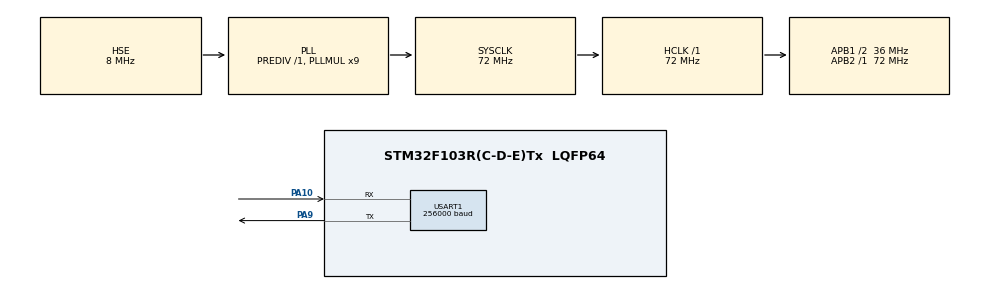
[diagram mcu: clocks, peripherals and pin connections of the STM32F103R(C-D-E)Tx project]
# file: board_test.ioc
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Mcu.Family=STM32F1
Mcu.Name=STM32F103R(C-D-E)Tx
Mcu.Package=LQFP64
NVIC.PriorityGroup=NVIC_PRIORITYGROUP_4
PA10.Mode=Asynchronous
PA10.Signal=USART1_RX
PA9.Mode=Asynchronous
PA9.Signal=USART1_TX
PD0-OSC_IN.Mode=HSE-External-Oscillator
PD0-OSC_IN.Signal=RCC_OSC_IN
PD1-OSC_OUT.Mode=HSE-External-Oscillator
PD1-OSC_OUT.Signal=RCC_OSC_OUT
ProjectManager.HeapSize=0x200
ProjectManager.StackSize=0x400
ProjectManager.TargetToolchain=MDK-ARM V5
RCC.AHBFreq_Value=72000000
RCC.APB1CLKDivider=RCC_HCLK_DIV2
RCC.APB1Freq_Value=36000000
RCC.APB1TimCLKDivider=1
RCC.APB1TimFreq_Value=36000000
RCC.APB2Freq_Value=72000000
RCC.APB2TimFreq_Value=72000000
RCC.HCLKFreq_Value=72000000
RCC.HSIState=RCC_HSI_ON
RCC.PLLMUL=RCC_PLL_MUL9
RCC.PLLSourceVirtual=RCC_PLLSOURCE_HSE
RCC.SYSCLKFreq_VALUE=72000000
RCC.SYSCLKSource=RCC_SYSCLKSOURCE_PLLCLK
RCC.USBFreq_Value=72000000
USART1.BaudRate=256000
board=board_test

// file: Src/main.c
/**
  ******************************************************************************
  * File Name          : main.c
  * Description        : Main program body
  ******************************************************************************
  *
  * COPYRIGHT(c) 2016 STMicroelectronics
  *
  * Redistribution and use in source and binary forms, with or without modification,
  * are permitted provided that the following conditions are met:
  *   1. Redistributions of source code must retain the above copyright notice,
  *      this list of conditions and the following disclaimer.
  *   2. Redistributions in binary form must reproduce the above copyright notice,
  *      this list of conditions and the following disclaimer in the documentation
  *      and/or other materials provided with the distribution.
  *   3. Neither the name of STMicroelectronics nor the names of its contributors
  *      may be used to endorse or promote products derived from this software
  *      without specific prior written permission.
  *
  * THIS SOFTWARE IS PROVIDED BY THE COPYRIGHT HOLDERS AND CONTRIBUTORS "AS IS"
  * AND ANY EXPRESS OR IMPLIED WARRANTIES, INCLUDING, BUT NOT LIMITED TO, THE
  * IMPLIED WARRANTIES OF MERCHANTABILITY AND FITNESS FOR A PARTICULAR PURPOSE ARE
  * DISCLAIMED. IN NO EVENT SHALL THE COPYRIGHT HOLDER OR CONTRIBUTORS BE LIABLE
  * FOR ANY DIRECT, INDIRECT, INCIDENTAL, SPECIAL, EXEMPLARY, OR CONSEQUENTIAL
  * DAMAGES (INCLUDING, BUT NOT LIMITED TO, PROCUREMENT OF SUBSTITUTE GOODS OR
  * SERVICES; LOSS OF USE, DATA, OR PROFITS; OR BUSINESS INTERRUPTION) HOWEVER
  * CAUSED AND ON ANY THEORY OF LIABILITY, WHETHER IN CONTRACT, STRICT LIABILITY,
  * OR TORT (INCLUDING NEGLIGENCE OR OTHERWISE) ARISING IN ANY WAY OUT OF THE USE
  * OF THIS SOFTWARE, EVEN IF ADVISED OF THE POSSIBILITY OF SUCH DAMAGE.
  *
  ******************************************************************************
  */
#include "stm32f1xx_hal.h"
#include "usart.h"
#include "gpio.h"

/* USER CODE BEGIN PV */
/* Private variables ---------------------------------------------------------*/

/* USER CODE END PV */

void SystemClock_Config(void);

/* USER CODE BEGIN PFP */
/* Private function prototypes -----------------------------------------------*/

/* USER CODE END PFP */

/* USER CODE BEGIN 0 */
/*
 * TimesNewRoman16.c
 *
 *  Created on: 11 июня 2016 г.
 *      Author: Администратор
 */

uint8_t TimesNewRoman16 [] =
{
/* char00 ('zero') */
0x00,0x00,0x00,0x00,0x00,0x00,0x00,0x00,
0x00,0x00,0x00,0x00,0x00,0x00,0x00,0x00,
0x00,0x00,0x00,0x00,0x00,0x00,0x00,0x00,
0x00,0x00,0x00,0x00,0x00,0x00,0x00,0x00,
0x00,0x00,0x00,0x00,0x00,0x00,0x00,0x00,
0x00,0x00,0x00,0x00,0x00,0x00,
/* char01 ('') */
0x00,0x00,0x00,0x00,0x00,0x00,0x00,0x00,
0x00,0x00,0x00,0x00,0x00,0x00,0x00,0x00,
0x00,0x00,0x00,0x00,0x00,0x00,0x00,0x00,
0x00,0x00,0x00,0x00,0x00,0x00,0x00,0x00,
0x00,0x00,0x00,0x00,0x00,0x00,0x00,0x00,
0x00,0x00,0x00,0x00,0x00,0x00,
/* char02 ('') */
0x00,0x00,0x00,0x00,0x00,0x00,0x00,0x00,
0x00,0x00,0x00,0x00,0x00,0x00,0x00,0x00,
0x00,0x00,0x00,0x00,0x00,0x00,0x00,0x00,
0x00,0x00,0x00,0x00,0x00,0x00,0x00,0x00,
0x00,0x00,0x00,0x00,0x00,0x00,0x00,0x00,
0x00,0x00,0x00,0x00,0x00,0x00,
/* char03 ('') */
0x00,0x00,0x00,0x00,0x00,0x00,0x00,0x00,
0x00,0x00,0x00,0x00,0x00,0x00,0x00,0x00,
0x00,0x00,0x00,0x00,0x00,0x00,0x00,0x00,
0x00,0x00,0x00,0x00,0x00,0x00,0x00,0x00,
0x00,0x00,0x00,0x00,0x00,0x00,0x00,0x00,
0x00,0x00,0x00,0x00,0x00,0x00,
/* char04 ('') */
0x00,0x00,0x00,0x00,0x00,0x00,0x00,0x00,
0x00,0x00,0x00,0x00,0x00,0x00,0x00,0x00,
0x00,0x00,0x00,0x00,0x00,0x00,0x00,0x00,
0x00,0x00,0x00,0x00,0x00,0x00,0x00,0x00,
0x00,0x00,0x00,0x00,0x00,0x00,0x00,0x00,
0x00,0x00,0x00,0x00,0x00,0x00,
/* char05 ('') */
0x00,0x00,0x00,0x00,0x00,0x00,0x00,0x00,
0x00,0x00,0x00,0x00,0x00,0x00,0x00,0x00,
0x00,0x00,0x00,0x00,0x00,0x00,0x00,0x00,
0x00,0x00,0x00,0x00,0x00,0x00,0x00,0x00,
0x00,0x00,0x00,0x00,0x00,0x00,0x00,0x00,
0x00,0x00,0x00,0x00,0x00,0x00,
/* char06 ('') */
0x00,0x00,0x00,0x00,0x00,0x00,0x00,0x00,
0x00,0x00,0x00,0x00,0x00,0x00,0x00,0x00,
0x00,0x00,0x00,0x00,0x00,0x00,0x00,0x00,
0x00,0x00,0x00,0x00,0x00,0x00,0x00,0x00,
0x00,0x00,0x00,0x00,0x00,0x00,0x00,0x00,
0x00,0x00,0x00,0x00,0x00,0x00,
/* char07 ('') */
0x00,0x00,0x00,0x00,0x00,0x00,0x00,0x00,
0x00,0x00,0x00,0x00,0x00,0x00,0x00,0x00,
0x00,0x00,0x00,0x00,0x00,0x00,0x00,0x00,
0x00,0x00,0x00,0x00,0x00,0x00,0x00,0x00,
0x00,0x00,0x00,0x00,0x00,0x00,0x00,0x00,
0x00,0x00,0x00,0x00,0x00,0x00,
/* char08 ('') */
0x00,0x00,0x00,0x00,0x00,0x00,0x00,0x00,
0x00,0x00,0x00,0x00,0x00,0x00,0x00,0x00,
0x00,0x00,0x00,0x00,0x00,0x00,0x00,0x00,
0x00,0x00,0x00,0x00,0x00,0x00,0x00,0x00,
0x00,0x00,0x00,0x00,0x00,0x00,0x00,0x00,
0x00,0x00,0x00,0x00,0x00,0x00,
/* char09 ('	') */
0x00,0x00,0x00,0x00,0x00,0x00,0x00,0x00,
0x00,0x00,0x00,0x00,0x00,0x00,0x00,0x00,
0x00,0x00,0x00,0x00,0x00,0x00,0x00,0x00,
0x00,0x00,0x00,0x00,0x00,0x00,0x00,0x00,
0x00,0x00,0x00,0x00,0x00,0x00,0x00,0x00,
0x00,0x00,0x00,0x00,0x00,0x00,
/* char0A ('LF') */
0x00,0x00,0x00,0x00,0x00,0x00,0x00,0x00,
0x00,0x00,0x00,0x00,0x00,0x00,0x00,0x00,
0x00,0x00,0x00,0x00,0x00,0x00,0x00,0x00,
0x00,0x00,0x00,0x00,0x00,0x00,0x00,0x00,
0x00,0x00,0x00,0x00,0x00,0x00,0x00,0x00,
0x00,0x00,0x00,0x00,0x00,0x00,
/* char0B ('') */
0x00,0x00,0x00,0x00,0x00,0x00,0x00,0x00,
0x00,0x00,0x00,0x00,0x00,0x00,0x00,0x00,
0x00,0x00,0x00,0x00,0x00,0x00,0x00,0x00,
0x00,0x00,0x00,0x00,0x00,0x00,0x00,0x00,
0x00,0x00,0x00,0x00,0x00,0x00,0x00,0x00,
0x00,0x00,0x00,0x00,0x00,0x00,
/* char0C ('') */
0x00,0x00,0x00,0x00,0x00,0x00,0x00,0x00,
0x00,0x00,0x00,0x00,0x00,0x00,0x00,0x00,
0x00,0x00,0x00,0x00,0x00,0x00,0x00,0x00,
0x00,0x00,0x00,0x00,0x00,0x00,0x00,0x00,
0x00,0x00,0x00,0x00,0x00,0x00,0x00,0x00,
0x00,0x00,0x00,0x00,0x00,0x00,
/* char0D ('CR') */
0x00,0x00,0x00,0x00,0x00,0x00,0x00,0x00,
0x00,0x00,0x00,0x00,0x00,0x00,0x00,0x00,
0x00,0x00,0x00,0x00,0x00,0x00,0x00,0x00,
0x00,0x00,0x00,0x00,0x00,0x00,0x00,0x00,
0x00,0x00,0x00,0x00,0x00,0x00,0x00,0x00,
0x00,0x00,0x00,0x00,0x00,0x00,
/* char0E ('') */
0x00,0x00,0x00,0x00,0x00,0x00,0x00,0x00,
0x00,0x00,0x00,0x00,0x00,0x00,0x00,0x00,
0x00,0x00,0x00,0x00,0x00,0x00,0x00,0x00,
0x00,0x00,0x00,0x00,0x00,0x00,0x00,0x00,
0x00,0x00,0x00,0x00,0x00,0x00,0x00,0x00,
0x00,0x00,0x00,0x00,0x00,0x00,
/* char0F ('') */
0x00,0x00,0x00,0x00,0x00,0x00,0x00,0x00,
0x00,0x00,0x00,0x00,0x00,0x00,0x00,0x00,
0x00,0x00,0x00,0x00,0x00,0x00,0x00,0x00,
0x00,0x00,0x00,0x00,0x00,0x00,0x00,0x00,
0x00,0x00,0x00,0x00,0x00,0x00,0x00,0x00,
0x00,0x00,0x00,0x00,0x00,0x00,
/* char10 ('') */
0x00,0x00,0x00,0x00,0x00,0x00,0x00,0x00,
0x00,0x00,0x00,0x00,0x00,0x00,0x00,0x00,
0x00,0x00,0x00,0x00,0x00,0x00,0x00,0x00,
0x00,0x00,0x00,0x00,0x00,0x00,0x00,0x00,
0x00,0x00,0x00,0x00,0x00,0x00,0x00,0x00,
0x00,0x00,0x00,0x00,0x00,0x00,
/* char11 ('') */
0x00,0x00,0x00,0x00,0x00,0x00,0x00,0x00,
0x00,0x00,0x00,0x00,0x00,0x00,0x00,0x00,
0x00,0x00,0x00,0x00,0x00,0x00,0x00,0x00,
0x00,0x00,0x00,0x00,0x00,0x00,0x00,0x00,
0x00,0x00,0x00,0x00,0x00,0x00,0x00,0x00,
0x00,0x00,0x00,0x00,0x00,0x00,
/* char12 ('') */
0x00,0x00,0x00,0x00,0x00,0x00,0x00,0x00,
0x00,0x00,0x00,0x00,0x00,0x00,0x00,0x00,
0x00,0x00,0x00,0x00,0x00,0x00,0x00,0x00,
0x00,0x00,0x00,0x00,0x00,0x00,0x00,0x00,
0x00,0x00,0x00,0x00,0x00,0x00,0x00,0x00,
0x00,0x00,0x00,0x00,0x00,0x00,
/* char13 ('') */
0x00,0x00,0x00,0x00,0x00,0x00,0x00,0x00,
0x00,0x00,0x00,0x00,0x00,0x00,0x00,0x00,
0x00,0x00,0x00,0x00,0x00,0x00,0x00,0x00,
0x00,0x00,0x00,0x00,0x00,0x00,0x00,0x00,
0x00,0x00,0x00,0x00,0x00,0x00,0x00,0x00,
0x00,0x00,0x00,0x00,0x00,0x00,
/* char14 ('') */
0x00,0x00,0x00,0x00,0x00,0x00,0x00,0x00,
0x00,0x00,0x00,0x00,0x00,0x00,0x00,0x00,
0x00,0x00,0x00,0x00,0x00,0x00,0x00,0x00,
0x00,0x00,0x00,0x00,0x00,0x00,0x00,0x00,
0x00,0x00,0x00,0x00,0x00,0x00,0x00,0x00,
0x00,0x00,0x00,0x00,0x00,0x00,
/* char15 ('') */
0x00,0x00,0x00,0x00,0x00,0x00,0x00,0x00,
0x00,0x00,0x00,0x00,0x00,0x00,0x00,0x00,
0x00,0x00,0x00,0x00,0x00,0x00,0x00,0x00,
0x00,0x00,0x00,0x00,0x00,0x00,0x00,0x00,
0x00,0x00,0x00,0x00,0x00,0x00,0x00,0x00,
0x00,0x00,0x00,0x00,0x00,0x00,
/* char16 ('') */
0x00,0x00,0x00,0x00,0x00,0x00,0x00,0x00,
0x00,0x00,0x00,0x00,0x00,0x00,0x00,0x00,
0x00,0x00,0x00,0x00,0x00,0x00,0x00,0x00,
0x00,0x00,0x00,0x00,0x00,0x00,0x00,0x00,
0x00,0x00,0x00,0x00,0x00,0x00,0x00,0x00,
0x00,0x00,0x00,0x00,0x00,0x00,
/* char17 ('') */
0x00,0x00,0x00,0x00,0x00,0x00,0x00,0x00,
0x00,0x00,0x00,0x00,0x00,0x00,0x00,0x00,
0x00,0x00,0x00,0x00,0x00,0x00,0x00,0x00,
0x00,0x00,0x00,0x00,0x00,0x00,0x00,0x00,
0x00,0x00,0x00,0x00,0x00,0x00,0x00,0x00,
0x00,0x00,0x00,0x00,0x00,0x00,
/* char18 ('') */
0x00,0x00,0x00,0x00,0x00,0x00,0x00,0x00,
0x00,0x00,0x00,0x00,0x00,0x00,0x00,0x00,
0x00,0x00,0x00,0x00,0x00,0x00,0x00,0x00,
0x00,0x00,0x00,0x00,0x00,0x00,0x00,0x00,
0x00,0x00,0x00,0x00,0x00,0x00,0x00,0x00,
0x00,0x00,0x00,0x00,0x00,0x00,
/* char19 ('end of medium') */
0x00,0x00,0x00,0x00,0x00,0x00,0x00,0x00,
0x00,0x00,0x00,0x00,0x00,0x00,0x00,0x00,
0x00,0x00,0x00,0x00,0x00,0x00,0x00,0x00,
0x00,0x00,0x00,0x00,0x00,0x00,0x00,0x00,
0x00,0x00,0x00,0x00,0x00,0x00,0x00,0x00,
0x00,0x00,0x00,0x00,0x00,0x00,
/* char1A ('substitute') */
0x00,0x00,0x00,0x00,0x00,0x00,0x00,0x00,
0x00,0x00,0x00,0x00,0x00,0x00,0x00,0x00,
0x00,0x00,0x00,0x00,0x00,0x00,0x00,0x00,
0x00,0x00,0x00,0x00,0x00,0x00,0x00,0x00,
0x00,0x00,0x00,0x00,0x00,0x00,0x00,0x00,
0x00,0x00,0x00,0x00,0x00,0x00,
/* char1B ('') */
0x00,0x00,0x00,0x00,0x00,0x00,0x00,0x00,
0x00,0x00,0x00,0x00,0x00,0x00,0x00,0x00,
0x00,0x00,0x00,0x00,0x00,0x00,0x00,0x00,
0x00,0x00,0x00,0x00,0x00,0x00,0x00,0x00,
0x00,0x00,0x00,0x00,0x00,0x00,0x00,0x00,
0x00,0x00,0x00,0x00,0x00,0x00,
/* char1C ('') */
0x00,0x00,0x00,0x00,0x00,0x00,0x00,0x00,
0x00,0x00,0x00,0x00,0x00,0x00,0x00,0x00,
0x00,0x00,0x00,0x00,0x00,0x00,0x00,0x00,
0x00,0x00,0x00,0x00,0x00,0x00,0x00,0x00,
0x00,0x00,0x00,0x00,0x00,0x00,0x00,0x00,
0x00,0x00,0x00,0x00,0x00,0x00,
/* char1D ('') */
0x00,0x00,0x00,0x00,0x00,0x00,0x00,0x00,
0x00,0x00,0x00,0x00,0x00,0x00,0x00,0x00,
0x00,0x00,0x00,0x00,0x00,0x00,0x00,0x00,
0x00,0x00,0x00,0x00,0x00,0x00,0x00,0x00,
0x00,0x00,0x00,0x00,0x00,0x00,0x00,0x00,
0x00,0x00,0x00,0x00,0x00,0x00,
/* char1E ('') */
0x00,0x00,0x00,0x00,0x00,0x00,0x00,0x00,
0x00,0x00,0x00,0x00,0x00,0x00,0x00,0x00,
0x00,0x00,0x00,0x00,0x00,0x00,0x00,0x00,
0x00,0x00,0x00,0x00,0x00,0x00,0x00,0x00,
0x00,0x00,0x00,0x00,0x00,0x00,0x00,0x00,
0x00,0x00,0x00,0x00,0x00,0x00,
/* char1F ('') */
0x00,0x00,0x00,0x00,0x00,0x00,0x00,0x00,
0x00,0x00,0x00,0x00,0x00,0x00,0x00,0x00,
0x00,0x00,0x00,0x00,0x00,0x00,0x00,0x00,
0x00,0x00,0x00,0x00,0x00,0x00,0x00,0x00,
0x00,0x00,0x00,0x00,0x00,0x00,0x00,0x00,
0x00,0x00,0x00,0x00,0x00,0x00,
/* char20 (' ') */
0x00,0x00,0x00,0x00,0x00,0x00,0x00,0x00,
0x00,0x00,0x00,0x00,0x00,0x00,0x00,0x00,
0x00,0x00,0x00,0x00,0x00,0x00,0x00,0x00,
0x00,0x00,0x00,0x00,0x00,0x00,0x00,0x00,
0x00,0x00,0x00,0x00,0x00,0x00,0x00,0x00,
0x00,0x00,0x00,0x00,0x00,0x00,
/* char21 ('!') */
0x00,0x00,0x00,0x00,0x00,0x00,0x00,0x00,
0x00,0x00,0x30,0x00,0x30,0x00,0x00,0x00,
0x00,0x00,0x20,0x00,0x20,0x00,0x20,0x00,
0x20,0x00,0x30,0x00,0x30,0x00,0x30,0x00,
0x30,0x00,0x30,0x00,0x30,0x00,0x00,0x00,
0x00,0x00,0x00,0x00,0x00,0x00,
/* char22 ('"') */
0x00,0x00,0x00,0x00,0x00,0x00,0x00,0x00,
0x00,0x00,0x00,0x00,0x00,0x00,0x00,0x00,
0x00,0x00,0x00,0x00,0x00,0x00,0x00,0x00,
0x00,0x00,0x44,0x00,0x44,0x00,0x66,0x00,
0x66,0x00,0x66,0x00,0x66,0x00,0x00,0x00,
0x00,0x00,0x00,0x00,0x00,0x00,
/* char23 ('#') */
0x00,0x00,0x00,0x00,0x00,0x00,0x00,0x00,
0x00,0x00,0x42,0x00,0x42,0x00,0x42,0x00,
0x21,0x00,0x21,0x00,0xFF,0xE0,0x21,0x00,
0x21,0x00,0x10,0x80,0xFF,0xE0,0x10,0x80,
0x10,0x80,0x10,0x80,0x08,0x40,0x08,0x40,
0x00,0x00,0x00,0x00,0x00,0x00,
/* char24 ('$') */
0x00,0x00,0x00,0x00,0x00,0x00,0x00,0x00,
0x04,0x00,0x3F,0x00,0x65,0x80,0x44,0xC0,
0x44,0xC0,0x04,0xC0,0x05,0x80,0x07,0x00,
0x1E,0x00,0x3C,0x00,0x74,0x00,0x64,0x80,
0x64,0x80,0x35,0x80,0x1F,0x00,0x04,0x00,
0x00,0x00,0x00,0x00,0x00,0x00,
/* char25 ('') */
0x00,0x00,0x00,0x00,0x00,0x00,0x00,0x00,
0x00,0x00,0x10,0x07,0x08,0x0D,0x04,0x18,
0x02,0x18,0x01,0x18,0x01,0x18,0x38,0x8D,
0x6C,0x47,0xC6,0x20,0xC6,0x20,0xC6,0x10,
0xC6,0x08,0x6C,0x04,0x38,0x02,0x00,0x00,
0x00,0x00,0x00,0x00,0x00,0x00,
/* char26 ('&') */
0x00,0x00,0x00,0x00,0x00,0x00,0x00,0x00,
0x00,0x00,0x3E,0x1C,0x71,0x7E,0x60,0xE3,
0x60,0xC0,0x61,0xC0,0x23,0xA0,0x13,0x10,
0x0E,0x18,0x07,0x3C,0x0C,0x80,0x0C,0x40,
0x0C,0x40,0x0C,0x40,0x07,0x80,0x00,0x00,
0x00,0x00,0x00,0x00,0x00,0x00,
/* char27 (''') */
0x00,0x00,0x00,0x00,0x00,0x00,0x00,0x00,
0x00,0x00,0x00,0x00,0x00,0x00,0x00,0x00,
0x00,0x00,0x00,0x00,0x00,0x00,0x00,0x00,
0x00,0x00,0x40,0x00,0x40,0x00,0x60,0x00,
0x60,0x00,0x60,0x00,0x60,0x00,0x00,0x00,
0x00,0x00,0x00,0x00,0x00,0x00,
/* char28 ('(') */
0x00,0x00,0x02,0x00,0x04,0x00,0x08,0x00,
0x10,0x00,0x30,0x00,0x30,0x00,0x60,0x00,
0x60,0x00,0x60,0x00,0x60,0x00,0x60,0x00,
0x60,0x00,0x60,0x00,0x20,0x00,0x30,0x00,
0x10,0x00,0x08,0x00,0x04,0x00,0x02,0x00,
0x00,0x00,0x00,0x00,0x00,0x00,
/* char29 (')') */
0x00,0x00,0x80,0x00,0x40,0x00,0x20,0x00,
0x10,0x00,0x18,0x00,0x08,0x00,0x0C,0x00,
0x0C,0x00,0x0C,0x00,0x0C,0x00,0x0C,0x00,
0x0C,0x00,0x0C,0x00,0x08,0x00,0x18,0x00,
0x10,0x00,0x20,0x00,0x40,0x00,0x80,0x00,
0x00,0x00,0x00,0x00,0x00,0x00,
/* char2A ('*') */
0x00,0x00,0x00,0x00,0x00,0x00,0x00,0x00,
0x00,0x00,0x00,0x00,0x00,0x00,0x00,0x00,
0x00,0x00,0x00,0x00,0x00,0x00,0x04,0x00,
0x04,0x00,0x35,0x80,0x35,0x80,0x0E,0x00,
0x35,0x80,0x35,0x80,0x04,0x00,0x04,0x00,
0x00,0x00,0x00,0x00,0x00,0x00,
/* char2B ('+') */
0x00,0x00,0x00,0x00,0x00,0x00,0x00,0x00,
0x00,0x00,0x00,0x00,0x00,0x00,0x04,0x00,
0x04,0x00,0x04,0x00,0x04,0x00,0x04,0x00,
0xFF,0xE0,0x04,0x00,0x04,0x00,0x04,0x00,
0x04,0x00,0x04,0x00,0x00,0x00,0x00,0x00,
0x00,0x00,0x00,0x00,0x00,0x00,
/* char2C (',') */
0x00,0x00,0x00,0x00,0x40,0x00,0x20,0x00,
0x10,0x00,0x70,0x00,0x60,0x00,0x00,0x00,
0x00,0x00,0x00,0x00,0x00,0x00,0x00,0x00,
0x00,0x00,0x00,0x00,0x00,0x00,0x00,0x00,
0x00,0x00,0x00,0x00,0x00,0x00,0x00,0x00,
0x00,0x00,0x00,0x00,0x00,0x00,
/* char2D ('-') */
0x00,0x00,0x00,0x00,0x00,0x00,0x00,0x00,
0x00,0x00,0x00,0x00,0x00,0x00,0x00,0x00,
0x00,0x00,0x7C,0x00,0x7C,0x00,0x00,0x00,
0x00,0x00,0x00,0x00,0x00,0x00,0x00,0x00,
0x00,0x00,0x00,0x00,0x00,0x00,0x00,0x00,
0x00,0x00,0x00,0x00,0x00,0x00,
/* char2E ('.') */
0x00,0x00,0x00,0x00,0x00,0x00,0x00,0x00,
0x00,0x00,0x60,0x00,0x60,0x00,0x00,0x00,
0x00,0x00,0x00,0x00,0x00,0x00,0x00,0x00,
0x00,0x00,0x00,0x00,0x00,0x00,0x00,0x00,
0x00,0x00,0x00,0x00,0x00,0x00,0x00,0x00,
0x00,0x00,0x00,0x00,0x00,0x00,
/* char2F ('/') */
0x00,0x00,0x00,0x00,0x00,0x00,0x00,0x00,
0x00,0x00,0x80,0x00,0x80,0x00,0x40,0x00,
0x40,0x00,0x40,0x00,0x20,0x00,0x20,0x00,
0x20,0x00,0x10,0x00,0x10,0x00,0x10,0x00,
0x08,0x00,0x08,0x00,0x08,0x00,0x04,0x00,
0x00,0x00,0x00,0x00,0x00,0x00,
/* char30 ('0') */
0x00,0x00,0x00,0x00,0x00,0x00,0x00,0x00,
0x00,0x00,0x0E,0x00,0x11,0x00,0x31,0x80,
0x20,0x80,0x60,0xC0,0x60,0xC0,0x60,0xC0,
0x60,0xC0,0x60,0xC0,0x60,0xC0,0x20,0x80,
0x31,0x80,0x11,0x00,0x0E,0x00,0x00,0x00,
0x00,0x00,0x00,0x00,0x00,0x00,
/* char31 ('1') */
0x00,0x00,0x00,0x00,0x00,0x00,0x00,0x00,
0x00,0x00,0x3F,0x00,0x0C,0x00,0x0C,0x00,
0x0C,0x00,0x0C,0x00,0x0C,0x00,0x0C,0x00,
0x0C,0x00,0x0C,0x00,0x0C,0x00,0x0C,0x00,
0x0C,0x00,0x3C,0x00,0x0C,0x00,0x00,0x00,
0x00,0x00,0x00,0x00,0x00,0x00,
/* char32 ('2') */
0x00,0x00,0x00,0x00,0x00,0x00,0x00,0x00,
0x00,0x00,0x7F,0x80,0x3F,0xC0,0x10,0x40,
0x08,0x00,0x04,0x00,0x02,0x00,0x02,0x00,
0x01,0x00,0x01,0x80,0x01,0x80,0x41,0x80,
0x63,0x80,0x3F,0x00,0x1E,0x00,0x00,0x00,
0x00,0x00,0x00,0x00,0x00,0x00,
/* char33 ('3') */
0x00,0x00,0x00,0x00,0x00,0x00,0x00,0x00,
0x00,0x00,0x7C,0x00,0x63,0x00,0x01,0x00,
0x01,0x80,0x01,0x80,0x03,0x80,0x07,0x00,
0x1F,0x00,0x0C,0x00,0x02,0x00,0x03,0x00,
0x43,0x00,0x27,0x00,0x1E,0x00,0x00,0x00,
0x00,0x00,0x00,0x00,0x00,0x00,
/* char34 ('4') */
0x00,0x00,0x00,0x00,0x00,0x00,0x00,0x00,
0x00,0x00,0x03,0x00,0x03,0x00,0x03,0x00,
0x03,0x00,0xFF,0xC0,0x83,0x00,0x43,0x00,
0x23,0x00,0x13,0x00,0x13,0x00,0x0B,0x00,
0x07,0x00,0x03,0x00,0x03,0x00,0x00,0x00,
0x00,0x00,0x00,0x00,0x00,0x00,
/* char35 ('5') */
0x00,0x00,0x00,0x00,0x00,0x00,0x00,0x00,
0x00,0x00,0x7C,0x00,0x62,0x00,0x01,0x00,
0x00,0x80,0x00,0x80,0x01,0x80,0x01,0x80,
0x03,0x80,0x0F,0x00,0x3E,0x00,0x38,0x00,
0x10,0x00,0x1F,0x00,0x0F,0x80,0x00,0x00,
0x00,0x00,0x00,0x00,0x00,0x00,
/* char36 ('6') */
0x00,0x00,0x00,0x00,0x00,0x00,0x00,0x00,
0x00,0x00,0x0F,0x00,0x31,0x80,0x30,0x80,
0x60,0xC0,0x60,0xC0,0x60,0xC0,0x61,0xC0,
0x71,0x80,0x2F,0x00,0x30,0x00,0x18,0x00,
0x0C,0x00,0x06,0x00,0x01,0xC0,0x00,0x00,
0x00,0x00,0x00,0x00,0x00,0x00,
/* char37 ('7') */
0x00,0x00,0x00,0x00,0x00,0x00,0x00,0x00,
0x00,0x00,0x08,0x00,0x04,0x00,0x04,0x00,
0x04,0x00,0x02,0x00,0x02,0x00,0x02,0x00,
0x01,0x00,0x01,0x00,0x01,0x00,0x00,0x80,
0x40,0x80,0x3F,0x80,0x3F,0xC0,0x00,0x00,
0x00,0x00,0x00,0x00,0x00,0x00,
/* char38 ('8') */
0x00,0x00,0x00,0x00,0x00,0x00,0x00,0x00,
0x00,0x00,0x1F,0x00,0x31,0x80,0x60,0xC0,
0x60,0xC0,0x61,0xC0,0x33,0x80,0x0F,0x00,
0x1E,0x00,0x39,0x80,0x70,0xC0,0x60,0xC0,
0x60,0xC0,0x31,0x80,0x1F,0x00,0x00,0x00,
0x00,0x00,0x00,0x00,0x00,0x00,
/* char39 ('9') */
0x00,0x00,0x00,0x00,0x00,0x00,0x00,0x00,
0x00,0x00,0x70,0x00,0x0C,0x00,0x06,0x00,
0x01,0x00,0x01,0x80,0x1F,0x80,0x30,0xC0,
0x70,0xC0,0x60,0xC0,0x60,0xC0,0x60,0xC0,
0x21,0x80,0x31,0x80,0x1E,0x00,0x00,0x00,
0x00,0x00,0x00,0x00,0x00,0x00,
/* char3A (':') */
0x00,0x00,0x00,0x00,0x00,0x00,0x00,0x00,
0x00,0x00,0x30,0x00,0x30,0x00,0x00,0x00,
0x00,0x00,0x00,0x00,0x00,0x00,0x00,0x00,
0x00,0x00,0x30,0x00,0x30,0x00,0x00,0x00,
0x00,0x00,0x00,0x00,0x00,0x00,0x00,0x00,
0x00,0x00,0x00,0x00,0x00,0x00,
/* char3B (';') */
0x00,0x00,0x00,0x00,0x40,0x00,0x20,0x00,
0x10,0x00,0x70,0x00,0x60,0x00,0x00,0x00,
0x00,0x00,0x00,0x00,0x00,0x00,0x00,0x00,
0x00,0x00,0x60,0x00,0x60,0x00,0x00,0x00,
0x00,0x00,0x00,0x00,0x00,0x00,0x00,0x00,
0x00,0x00,0x00,0x00,0x00,0x00,
/* char3C ('<') */
0x00,0x00,0x00,0x00,0x00,0x00,0x00,0x00,
0x00,0x00,0x00,0x00,0x00,0x00,0x00,0x20,
0x00,0xC0,0x07,0x00,0x18,0x00,0x60,0x00,
0x80,0x00,0x60,0x00,0x18,0x00,0x07,0x00,
0x00,0xC0,0x00,0x20,0x00,0x00,0x00,0x00,
0x00,0x00,0x00,0x00,0x00,0x00,
/* char3D ('=') */
0x00,0x00,0x00,0x00,0x00,0x00,0x00,0x00,
0x00,0x00,0x00,0x00,0x00,0x00,0x00,0x00,
0x00,0x00,0x00,0x00,0xFF,0xF0,0x00,0x00,
0x00,0x00,0x00,0x00,0xFF,0xF0,0x00,0x00,
0x00,0x00,0x00,0x00,0x00,0x00,0x00,0x00,
0x00,0x00,0x00,0x00,0x00,0x00,
/* char3E ('>') */
0x00,0x00,0x00,0x00,0x00,0x00,0x00,0x00,
0x00,0x00,0x00,0x00,0x00,0x00,0x80,0x00,
0x60,0x00,0x1C,0x00,0x03,0x00,0x00,0xC0,
0x00,0x20,0x00,0xC0,0x03,0x00,0x1C,0x00,
0x60,0x00,0x80,0x00,0x00,0x00,0x00,0x00,
0x00,0x00,0x00,0x00,0x00,0x00,
/* char3F ('?') */
0x00,0x00,0x00,0x00,0x00,0x00,0x00,0x00,
0x00,0x00,0x0C,0x00,0x0C,0x00,0x00,0x00,
0x08,0x00,0x08,0x00,0x04,0x00,0x02,0x00,
0x03,0x00,0x01,0x00,0x61,0x80,0x61,0x80,
0x41,0x80,0x23,0x00,0x1E,0x00,0x00,0x00,
0x00,0x00,0x00,0x00,0x00,0x00,
/* char40 ('@') */
0x01,0xF8,0x06,0x06,0x08,0x01,0x10,0x00,
0x20,0x00,0x23,0x9E,0x46,0x79,0x46,0x18,
0x46,0x18,0x46,0x0C,0x43,0x0C,0x43,0x04,
0x61,0x84,0x21,0x86,0x20,0xCE,0x10,0x72,
0x18,0x00,0x0C,0x01,0x03,0x06,0x00,0xFC,
0x00,0x00,0x00,0x00,0x00,0x00,
/* char41 ('A') */
0x00,0x00,0x00,0x00,0x00,0x00,0x00,0x00,
0x00,0x00,0xF0,0x7C,0x60,0x38,0x20,0x30,
0x20,0x30,0x10,0x60,0x1F,0xE0,0x08,0x60,
0x08,0xC0,0x04,0xC0,0x04,0xC0,0x05,0x80,
0x03,0x80,0x03,0x00,0x01,0x00,0x00,0x00,
0x00,0x00,0x00,0x00,0x00,0x00,
/* char42 ('B') */
0x00,0x00,0x00,0x00,0x00,0x00,0x00,0x00,
0x00,0x00,0xFF,0xE0,0x30,0x30,0x30,0x18,
0x30,0x18,0x30,0x18,0x30,0x38,0x30,0x70,
0x3F,0xC0,0x30,0x60,0x30,0x30,0x30,0x30,
0x30,0x30,0x30,0x60,0xFF,0xC0,0x00,0x00,
0x00,0x00,0x00,0x00,0x00,0x00,
/* char43 ('C') */
0x00,0x00,0x00,0x00,0x00,0x00,0x00,0x00,
0x00,0x00,0x07,0xC0,0x1C,0x20,0x30,0x10,
0x30,0x08,0x60,0x00,0x60,0x00,0x60,0x00,
0x60,0x00,0x60,0x00,0x60,0x08,0x30,0x18,
0x10,0x18,0x0C,0x38,0x07,0xC8,0x00,0x00,
0x00,0x00,0x00,0x00,0x00,0x00,
/* char44 ('D') */
0x00,0x00,0x00,0x00,0x00,0x00,0x00,0x00,
0x00,0x00,0xFF,0xC0,0x30,0x60,0x30,0x30,
0x30,0x18,0x30,0x0C,0x30,0x0C,0x30,0x0C,
0x30,0x0C,0x30,0x0C,0x30,0x0C,0x30,0x18,
0x30,0x38,0x30,0x70,0xFF,0xC0,0x00,0x00,
0x00,0x00,0x00,0x00,0x00,0x00,
/* char45 ('E') */
0x00,0x00,0x00,0x00,0x00,0x00,0x00,0x00,
0x00,0x00,0xFF,0xF0,0x30,0x30,0x30,0x10,
0x30,0x08,0x30,0x00,0x30,0x40,0x30,0x40,
0x3F,0xC0,0x30,0x40,0x30,0x40,0x30,0x00,
0x30,0x10,0x30,0x30,0xFF,0xF0,0x00,0x00,
0x00,0x00,0x00,0x00,0x00,0x00,
/* char46 ('F') */
0x00,0x00,0x00,0x00,0x00,0x00,0x00,0x00,
0x00,0x00,0xFC,0x00,0x30,0x00,0x30,0x00,
0x30,0x00,0x30,0x00,0x30,0x80,0x30,0x80,
0x3F,0x80,0x30,0x80,0x30,0x80,0x30,0x00,
0x30,0x20,0x30,0x60,0xFF,0xE0,0x00,0x00,
0x00,0x00,0x00,0x00,0x00,0x00,
/* char47 ('G') */
0x00,0x00,0x00,0x00,0x00,0x00,0x00,0x00,
0x00,0x00,0x07,0xE0,0x1C,0x38,0x38,0x18,
0x30,0x18,0x60,0x18,0x60,0x18,0x60,0x18,
0x60,0x7E,0x60,0x00,0x20,0x00,0x30,0x08,
0x10,0x18,0x0C,0x38,0x07,0xC8,0x00,0x00,
0x00,0x00,0x00,0x00,0x00,0x00,
/* char48 ('H') */
0x00,0x00,0x00,0x00,0x00,0x00,0x00,0x00,
0x00,0x00,0xFC,0x7E,0x30,0x18,0x30,0x18,
0x30,0x18,0x30,0x18,0x30,0x18,0x30,0x18,
0x3F,0xF8,0x30,0x18,0x30,0x18,0x30,0x18,
0x30,0x18,0x30,0x18,0xFC,0x7E,0x00,0x00,
0x00,0x00,0x00,0x00,0x00,0x00,
/* char49 ('I') */
0x00,0x00,0x00,0x00,0x00,0x00,0x00,0x00,
0x00,0x00,0xFC,0x00,0x30,0x00,0x30,0x00,
0x30,0x00,0x30,0x00,0x30,0x00,0x30,0x00,
0x30,0x00,0x30,0x00,0x30,0x00,0x30,0x00,
0x30,0x00,0x30,0x00,0xFC,0x00,0x00,0x00,
0x00,0x00,0x00,0x00,0x00,0x00,
/* char4A ('J') */
0x00,0x00,0x00,0x00,0x00,0x00,0x00,0x00,
0x00,0x00,0x70,0x00,0xE8,0x00,0xCC,0x00,
0x0C,0x00,0x0C,0x00,0x0C,0x00,0x0C,0x00,
0x0C,0x00,0x0C,0x00,0x0C,0x00,0x0C,0x00,
0x0C,0x00,0x0C,0x00,0x3F,0x00,0x00,0x00,
0x00,0x00,0x00,0x00,0x00,0x00,
/* char4B ('K') */
0x00,0x00,0x00,0x00,0x00,0x00,0x00,0x00,
0x00,0x00,0xFC,0x7E,0x30,0x38,0x30,0x70,
0x30,0xE0,0x31,0xC0,0x33,0x80,0x37,0x00,
0x3E,0x00,0x32,0x00,0x31,0x00,0x30,0x80,
0x30,0x40,0x30,0x30,0xFC,0x7C,0x00,0x00,
0x00,0x00,0x00,0x00,0x00,0x00,
/* char4C ('L') */
0x00,0x00,0x00,0x00,0x00,0x00,0x00,0x00,
0x00,0x00,0xFF,0xE0,0x30,0x60,0x30,0x30,
0x30,0x10,0x30,0x00,0x30,0x00,0x30,0x00,
0x30,0x00,0x30,0x00,0x30,0x00,0x30,0x00,
0x30,0x00,0x30,0x00,0xFC,0x00,0x00,0x00,
0x00,0x00,0x00,0x00,0x00,0x00,
/* char4D ('M') */
0x00,0x00,0x00,0x00,0x00,0x00,0x00,0x00,
0x00,0x00,0xF8,0x8F,0x21,0x83,0x21,0xC3,
0x21,0xC3,0x23,0x23,0x23,0x23,0x27,0x13,
0x26,0x13,0x2E,0x0B,0x2C,0x0B,0x2C,0x0B,
0x3C,0x07,0x38,0x07,0xF8,0x03,0x00,0x00,
0x00,0x00,0x00,0x00,0x00,0x00,
/* char4E ('N') */
0x00,0x00,0x00,0x00,0x00,0x00,0x00,0x00,
0x00,0x00,0x7C,0x04,0x10,0x0C,0x10,0x1C,
0x10,0x3C,0x10,0x34,0x10,0x64,0x10,0xC4,
0x11,0x84,0x13,0x04,0x17,0x04,0x1E,0x04,
0x1C,0x04,0x38,0x04,0xF0,0x1E,0x00,0x00,
0x00,0x00,0x00,0x00,0x00,0x00,
/* char4F ('O') */
0x00,0x00,0x00,0x00,0x00,0x00,0x00,0x00,
0x00,0x00,0x07,0xC0,0x18,0x30,0x30,0x18,
0x30,0x18,0x60,0x0C,0x60,0x0C,0x60,0x0C,
0x60,0x0C,0x60,0x0C,0x60,0x0C,0x30,0x18,
0x30,0x18,0x18,0x30,0x07,0xC0,0x00,0x00,
0x00,0x00,0x00,0x00,0x00,0x00,
/* char50 ('P') */
0x00,0x00,0x00,0x00,0x00,0x00,0x00,0x00,
0x00,0x00,0xFC,0x00,0x30,0x00,0x30,0x00,
0x30,0x00,0x30,0x00,0x30,0x00,0x3F,0x80,
0x30,0xC0,0x30,0x60,0x30,0x60,0x30,0x60,
0x30,0x60,0x30,0xC0,0xFF,0x80,0x00,0x00,
0x00,0x00,0x00,0x00,0x00,0x00,
/* char51 ('Q') */
0x00,0x00,0x00,0x1C,0x00,0x70,0x00,0xC0,
0x03,0x80,0x07,0xC0,0x18,0x30,0x30,0x18,
0x30,0x18,0x60,0x0C,0x60,0x0C,0x60,0x0C,
0x60,0x0C,0x60,0x0C,0x60,0x0C,0x30,0x18,
0x30,0x18,0x18,0x30,0x07,0xC0,0x00,0x00,
0x00,0x00,0x00,0x00,0x00,0x00,
/* char52 ('R') */
0x00,0x00,0x00,0x00,0x00,0x00,0x00,0x00,
0x00,0x00,0xFC,0x3C,0x30,0x70,0x30,0xE0,
0x30,0xC0,0x31,0x80,0x33,0x80,0x33,0x00,
0x3F,0x80,0x30,0xC0,0x30,0x60,0x30,0x60,
0x30,0x60,0x30,0xC0,0xFF,0x80,0x00,0x00,
0x00,0x00,0x00,0x00,0x00,0x00,
/* char53 ('S') */
0x00,0x00,0x00,0x00,0x00,0x00,0x00,0x00,
0x00,0x00,0x4F,0x00,0x71,0x80,0x60,0xC0,
0x40,0xC0,0x41,0xC0,0x03,0x80,0x07,0x00,
0x1E,0x00,0x38,0x00,0x70,0x80,0x60,0x80,
0x61,0x80,0x33,0x80,0x1C,0x80,0x00,0x00,
0x00,0x00,0x00,0x00,0x00,0x00,
/* char54 ('T') */
0x00,0x00,0x00,0x00,0x00,0x00,0x00,0x00,
0x00,0x00,0x1F,0x80,0x06,0x00,0x06,0x00,
0x06,0x00,0x06,0x00,0x06,0x00,0x06,0x00,
0x06,0x00,0x06,0x00,0x06,0x00,0x06,0x00,
0x86,0x10,0xC6,0x30,0xFF,0xF0,0x00,0x00,
0x00,0x00,0x00,0x00,0x00,0x00,
/* char55 ('U') */
0x00,0x00,0x00,0x00,0x00,0x00,0x00,0x00,
0x00,0x00,0x07,0xC0,0x1C,0x30,0x18,0x10,
0x30,0x08,0x30,0x08,0x30,0x08,0x30,0x08,
0x30,0x08,0x30,0x08,0x30,0x08,0x30,0x08,
0x30,0x08,0x30,0x08,0xFC,0x3E,0x00,0x00,
0x00,0x00,0x00,0x00,0x00,0x00,
/* char56 ('V') */
0x00,0x00,0x00,0x00,0x00,0x00,0x00,0x00,
0x00,0x00,0x01,0x80,0x01,0x80,0x03,0x40,
0x03,0x40,0x03,0x40,0x06,0x20,0x06,0x20,
0x0C,0x10,0x0C,0x10,0x08,0x10,0x18,0x08,
0x18,0x08,0x38,0x0C,0xFC,0x1E,0x00,0x00,
0x00,0x00,0x00,0x00,0x00,0x00,
/* char57 ('W') */
0x00,0x00,0x00,0x00,0x00,0x00,0x00,0x00,
0x00,0x00,0x04,0x04,0x06,0x04,0x06,0x0E,
0x0E,0x0E,0x0D,0x1A,0x0D,0x1B,0x19,0x19,
0x18,0xB1,0x18,0xB1,0x30,0xB0,0x30,0x60,
0x30,0x60,0x70,0xE0,0xF9,0xF1,0x00,0x00,
0x00,0x00,0x00,0x00,0x00,0x00,
/* char58 ('X') */
0x00,0x00,0x00,0x00,0x00,0x00,0x00,0x00,
0x00,0x00,0xF8,0x7C,0x30,0x38,0x08,0x30,
0x0C,0x60,0x04,0xC0,0x03,0xC0,0x01,0x80,
0x03,0x00,0x07,0x80,0x06,0x40,0x0C,0x20,
0x18,0x30,0x38,0x18,0xFE,0x7C,0x00,0x00,
0x00,0x00,0x00,0x00,0x00,0x00,
/* char59 ('Y') */
0x00,0x00,0x00,0x00,0x00,0x00,0x00,0x00,
0x00,0x00,0x07,0xE0,0x01,0x80,0x01,0x80,
0x01,0x80,0x01,0x80,0x01,0x80,0x01,0x80,
0x03,0x40,0x06,0x40,0x06,0x20,0x0C,0x10,
0x18,0x10,0x38,0x08,0xFE,0x3E,0x00,0x00,
0x00,0x00,0x00,0x00,0x00,0x00,
/* char5A ('Z') */
0x00,0x00,0x00,0x00,0x00,0x00,0x00,0x00,
0x00,0x00,0xFF,0xE0,0x60,0x30,0x60,0x10,
0x30,0x10,0x18,0x00,0x0C,0x00,0x0C,0x00,
0x06,0x00,0x03,0x00,0x03,0x00,0x41,0x80,
0x40,0xC0,0x60,0xC0,0x7F,0xE0,0x00,0x00,
0x00,0x00,0x00,0x00,0x00,0x00,
/* char5B ('[') */
0x00,0x00,0x7C,0x00,0x60,0x00,0x60,0x00,
0x60,0x00,0x60,0x00,0x60,0x00,0x60,0x00,
0x60,0x00,0x60,0x00,0x60,0x00,0x60,0x00,
0x60,0x00,0x60,0x00,0x60,0x00,0x60,0x00,
0x60,0x00,0x60,0x00,0x60,0x00,0x7C,0x00,
0x00,0x00,0x00,0x00,0x00,0x00,
/* char5C ('\') */
0x00,0x00,0x00,0x00,0x00,0x00,0x00,0x00,
0x00,0x00,0x04,0x00,0x08,0x00,0x08,0x00,
0x08,0x00,0x10,0x00,0x10,0x00,0x10,0x00,
0x20,0x00,0x20,0x00,0x20,0x00,0x40,0x00,
0x40,0x00,0x40,0x00,0x80,0x00,0x80,0x00,
0x00,0x00,0x00,0x00,0x00,0x00,
/* char5D (']') */
0x00,0x00,0xF8,0x00,0x18,0x00,0x18,0x00,
0x18,0x00,0x18,0x00,0x18,0x00,0x18,0x00,
0x18,0x00,0x18,0x00,0x18,0x00,0x18,0x00,
0x18,0x00,0x18,0x00,0x18,0x00,0x18,0x00,
0x18,0x00,0x18,0x00,0x18,0x00,0xF8,0x00,
0x00,0x00,0x00,0x00,0x00,0x00,
/* char5E ('^') */
0x00,0x00,0x00,0x00,0x00,0x00,0x00,0x00,
0x00,0x00,0x00,0x00,0x00,0x00,0x00,0x00,
0x00,0x00,0x00,0x00,0x00,0x00,0x00,0x00,
0x80,0x40,0x40,0x80,0x40,0x80,0x21,0x00,
0x12,0x00,0x12,0x00,0x0C,0x00,0x00,0x00,
0x00,0x00,0x00,0x00,0x00,0x00,
/* char5F ('_') */
0x00,0x00,0xFF,0xE0,0x00,0x00,0x00,0x00,
0x00,0x00,0x00,0x00,0x00,0x00,0x00,0x00,
0x00,0x00,0x00,0x00,0x00,0x00,0x00,0x00,
0x00,0x00,0x00,0x00,0x00,0x00,0x00,0x00,
0x00,0x00,0x00,0x00,0x00,0x00,0x00,0x00,
0x00,0x00,0x00,0x00,0x00,0x00,
/* char60 ('`') */
0x00,0x00,0x00,0x00,0x00,0x00,0x00,0x00,
0x00,0x00,0x00,0x00,0x00,0x00,0x00,0x00,
0x00,0x00,0x00,0x00,0x00,0x00,0x00,0x00,
0x00,0x00,0x00,0x00,0x00,0x00,0x00,0x00,
0x10,0x00,0x30,0x00,0x60,0x00,0x00,0x00,
0x00,0x00,0x00,0x00,0x00,0x00,
/* char61 ('a') */
0x00,0x00,0x00,0x00,0x00,0x00,0x00,0x00,
0x00,0x00,0x3B,0x80,0x67,0x00,0x63,0x00,
0x63,0x00,0x33,0x00,0x1B,0x00,0x07,0x00,
0x63,0x00,0x63,0x00,0x3E,0x00,0x00,0x00,
0x00,0x00,0x00,0x00,0x00,0x00,0x00,0x00,
0x00,0x00,0x00,0x00,0x00,0x00,
/* char62 ('b') */
0x00,0x00,0x00,0x00,0x00,0x00,0x00,0x00,
0x00,0x00,0x3C,0x00,0x73,0x00,0x61,0x00,
0x61,0x80,0x61,0x80,0x61,0x80,0x61,0x80,
0x61,0x80,0x73,0x00,0x6E,0x00,0x60,0x00,
0x60,0x00,0x60,0x00,0xE0,0x00,0x60,0x00,
0x00,0x00,0x00,0x00,0x00,0x00,
/* char63 ('c') */
0x00,0x00,0x00,0x00,0x00,0x00,0x00,0x00,
0x00,0x00,0x1C,0x00,0x3E,0x00,0x71,0x00,
0x60,0x00,0x60,0x00,0x60,0x00,0x60,0x00,
0x61,0x00,0x33,0x00,0x1E,0x00,0x00,0x00,
0x00,0x00,0x00,0x00,0x00,0x00,0x00,0x00,
0x00,0x00,0x00,0x00,0x00,0x00,
/* char64 ('d') */
0x00,0x00,0x00,0x00,0x00,0x00,0x00,0x00,
0x00,0x00,0x1D,0x80,0x33,0xC0,0x61,0x80,
0x61,0x80,0x61,0x80,0x61,0x80,0x61,0x80,
0x21,0x80,0x33,0x80,0x1D,0x80,0x01,0x80,
0x01,0x80,0x01,0x80,0x03,0x80,0x01,0x80,
0x00,0x00,0x00,0x00,0x00,0x00,
/* char65 ('e') */
0x00,0x00,0x00,0x00,0x00,0x00,0x00,0x00,
0x00,0x00,0x1E,0x00,0x3F,0x00,0x70,0x80,
0x60,0x00,0x60,0x00,0x60,0x00,0x7F,0x80,
0x61,0x80,0x33,0x00,0x1E,0x00,0x00,0x00,
0x00,0x00,0x00,0x00,0x00,0x00,0x00,0x00,
0x00,0x00,0x00,0x00,0x00,0x00,
/* char66 ('f') */
0x00,0x00,0x00,0x00,0x00,0x00,0x00,0x00,
0x00,0x00,0xFC,0x00,0x30,0x00,0x30,0x00,
0x30,0x00,0x30,0x00,0x30,0x00,0x30,0x00,
0x30,0x00,0x30,0x00,0xFC,0x00,0x30,0x00,
0x30,0x00,0x30,0x00,0x10,0x00,0x0E,0x00,
0x00,0x00,0x00,0x00,0x00,0x00,
/* char67 ('g') */
0x00,0x00,0x7F,0x00,0xC0,0x80,0x80,0x40,
0x40,0x40,0x3F,0xC0,0x7F,0x80,0x60,0x00,
0x1E,0x00,0x33,0x00,0x61,0x80,0x61,0x80,
0x61,0x80,0x33,0xC0,0x1E,0x00,0x00,0x00,
0x00,0x00,0x00,0x00,0x00,0x00,0x00,0x00,
0x00,0x00,0x00,0x00,0x00,0x00,
/* char68 ('h') */
0x00,0x00,0x00,0x00,0x00,0x00,0x00,0x00,
0x00,0x00,0xF3,0xC0,0x61,0x80,0x61,0x80,
0x61,0x80,0x61,0x80,0x61,0x80,0x61,0x80,
0x61,0x80,0x79,0x80,0x67,0x00,0x60,0x00,
0x60,0x00,0x60,0x00,0xE0,0x00,0x60,0x00,
0x00,0x00,0x00,0x00,0x00,0x00,
/* char69 ('i') */
0x00,0x00,0x00,0x00,0x00,0x00,0x00,0x00,
0x00,0x00,0x78,0x00,0x30,0x00,0x30,0x00,
0x30,0x00,0x30,0x00,0x30,0x00,0x30,0x00,
0x30,0x00,0x70,0x00,0x30,0x00,0x00,0x00,
0x00,0x00,0x00,0x00,0x30,0x00,0x30,0x00,
0x00,0x00,0x00,0x00,0x00,0x00,
/* char6A ('j') */
0x00,0x00,0xF0,0x00,0xC8,0x00,0x0C,0x00,
0x0C,0x00,0x0C,0x00,0x0C,0x00,0x0C,0x00,
0x0C,0x00,0x0C,0x00,0x0C,0x00,0x0C,0x00,
0x0C,0x00,0x1C,0x00,0x0C,0x00,0x00,0x00,
0x00,0x00,0x00,0x00,0x0C,0x00,0x0C,0x00,
0x00,0x00,0x00,0x00,0x00,0x00,
/* char6B ('k') */
0x00,0x00,0x00,0x00,0x00,0x00,0x00,0x00,
0x00,0x00,0xF3,0xC0,0x61,0x80,0x63,0x00,
0x66,0x00,0x6C,0x00,0x78,0x00,0x68,0x00,
0x64,0x00,0x62,0x00,0x67,0x80,0x60,0x00,
0x60,0x00,0x60,0x00,0xE0,0x00,0x60,0x00,
0x00,0x00,0x00,0x00,0x00,0x00,
/* char6C ('l') */
0x00,0x00,0x00,0x00,0x00,0x00,0x00,0x00,
0x00,0x00,0x78,0x00,0x30,0x00,0x30,0x00,
0x30,0x00,0x30,0x00,0x30,0x00,0x30,0x00,
0x30,0x00,0x30,0x00,0x30,0x00,0x30,0x00,
0x30,0x00,0x30,0x00,0x70,0x00,0x30,0x00,
0x00,0x00,0x00,0x00,0x00,0x00,
/* char6D ('m') */
0x00,0x00,0x00,0x00,0x00,0x00,0x00,0x00,
0x00,0x00,0xF3,0xCF,0x61,0x86,0x61,0x86,
0x61,0x86,0x61,0x86,0x61,0x86,0x61,0x86,
0x61,0x86,0xF9,0xE6,0x67,0x1C,0x00,0x00,
0x00,0x00,0x00,0x00,0x00,0x00,0x00,0x00,
0x00,0x00,0x00,0x00,0x00,0x00,
/* char6E ('n') */
0x00,0x00,0x00,0x00,0x00,0x00,0x00,0x00,
0x00,0x00,0xF3,0xC0,0x61,0x80,0x61,0x80,
0x61,0x80,0x61,0x80,0x61,0x80,0x61,0x80,
0x61,0x80,0xF9,0x80,0x67,0x00,0x00,0x00,
0x00,0x00,0x00,0x00,0x00,0x00,0x00,0x00,
0x00,0x00,0x00,0x00,0x00,0x00,
/* char6F ('o') */
0x00,0x00,0x00,0x00,0x00,0x00,0x00,0x00,
0x00,0x00,0x1E,0x00,0x31,0x80,0x30,0x80,
0x60,0xC0,0x60,0xC0,0x60,0xC0,0x60,0xC0,
0x21,0x80,0x33,0x80,0x0E,0x00,0x00,0x00,
0x00,0x00,0x00,0x00,0x00,0x00,0x00,0x00,
0x00,0x00,0x00,0x00,0x00,0x00,
/* char70 ('p') */
0x00,0x00,0xF0,0x00,0x60,0x00,0x60,0x00,
0x60,0x00,0x6E,0x00,0x73,0x00,0x61,0x00,
0x61,0x80,0x61,0x80,0x61,0x80,0x61,0x80,
0x61,0x80,0xF3,0x00,0x6E,0x00,0x00,0x00,
0x00,0x00,0x00,0x00,0x00,0x00,0x00,0x00,
0x00,0x00,0x00,0x00,0x00,0x00,
/* char71 ('q') */
0x00,0x00,0x03,0xC0,0x01,0x80,0x01,0x80,
0x01,0x80,0x1D,0x80,0x33,0x80,0x61,0x80,
0x61,0x80,0x61,0x80,0x61,0x80,0x61,0x80,
0x21,0x80,0x33,0x80,0x1E,0x80,0x00,0x00,
0x00,0x00,0x00,0x00,0x00,0x00,0x00,0x00,
0x00,0x00,0x00,0x00,0x00,0x00,
/* char72 ('r') */
0x00,0x00,0x00,0x00,0x00,0x00,0x00,0x00,
0x00,0x00,0xF0,0x00,0x60,0x00,0x60,0x00,
0x60,0x00,0x60,0x00,0x60,0x00,0x60,0x00,
0x60,0x00,0xF6,0x00,0x6E,0x00,0x00,0x00,
0x00,0x00,0x00,0x00,0x00,0x00,0x00,0x00,
0x00,0x00,0x00,0x00,0x00,0x00,
/* char73 ('s') */
0x00,0x00,0x00,0x00,0x00,0x00,0x00,0x00,
0x00,0x00,0x5C,0x00,0x62,0x00,0x42,0x00,
0x06,0x00,0x3E,0x00,0x7C,0x00,0x60,0x00,
0x42,0x00,0x46,0x00,0x3A,0x00,0x00,0x00,
0x00,0x00,0x00,0x00,0x00,0x00,0x00,0x00,
0x00,0x00,0x00,0x00,0x00,0x00,
/* char74 ('t') */
0x00,0x00,0x00,0x00,0x00,0x00,0x00,0x00,
0x00,0x00,0x38,0x00,0x64,0x00,0x60,0x00,
0x60,0x00,0x60,0x00,0x60,0x00,0x60,0x00,
0x60,0x00,0x60,0x00,0xF8,0x00,0x60,0x00,
0x60,0x00,0x20,0x00,0x00,0x00,0x00,0x00,
0x00,0x00,0x00,0x00,0x00,0x00,
/* char75 ('u') */
0x00,0x00,0x00,0x00,0x00,0x00,0x00,0x00,
0x00,0x00,0x3D,0x80,0x63,0xC0,0x61,0x80,
0x61,0x80,0x61,0x80,0x61,0x80,0x61,0x80,
0x61,0x80,0x61,0x80,0xE3,0x80,0x00,0x00,
0x00,0x00,0x00,0x00,0x00,0x00,0x00,0x00,
0x00,0x00,0x00,0x00,0x00,0x00,
/* char76 ('v') */
0x00,0x00,0x00,0x00,0x00,0x00,0x00,0x00,
0x00,0x00,0x0C,0x00,0x0C,0x00,0x1A,0x00,
0x1A,0x00,0x19,0x00,0x31,0x00,0x31,0x00,
0x30,0x80,0x60,0x80,0xF9,0xC0,0x00,0x00,
0x00,0x00,0x00,0x00,0x00,0x00,0x00,0x00,
0x00,0x00,0x00,0x00,0x00,0x00,
/* char77 ('w') */
0x00,0x00,0x00,0x00,0x00,0x00,0x00,0x00,
0x00,0x00,0x08,0x20,0x18,0x60,0x1C,0x70,
0x1C,0x70,0x32,0xD0,0x32,0xC8,0x31,0xC8,
0x61,0x84,0x61,0x84,0xF3,0xCE,0x00,0x00,
0x00,0x00,0x00,0x00,0x00,0x00,0x00,0x00,
0x00,0x00,0x00,0x00,0x00,0x00,
/* char78 ('x') */
0x00,0x00,0x00,0x00,0x00,0x00,0x00,0x00,
0x00,0x00,0xE3,0xC0,0x41,0x80,0x23,0x00,
0x16,0x00,0x0C,0x00,0x0C,0x00,0x1C,0x00,
0x32,0x00,0x61,0x00,0xF3,0xC0,0x00,0x00,
0x00,0x00,0x00,0x00,0x00,0x00,0x00,0x00,
0x00,0x00,0x00,0x00,0x00,0x00,
/* char79 ('y') */
0x00,0x00,0x70,0x00,0x78,0x00,0x08,0x00,
0x04,0x00,0x04,0x00,0x06,0x00,0x0E,0x00,
0x0E,0x00,0x19,0x00,0x19,0x00,0x19,0x00,
0x30,0x80,0x70,0x80,0xF9,0x80,0x00,0x00,
0x00,0x00,0x00,0x00,0x00,0x00,0x00,0x00,
0x00,0x00,0x00,0x00,0x00,0x00,
/* char7A ('z') */
0x00,0x00,0x00,0x00,0x00,0x00,0x00,0x00,
0x00,0x00,0xFF,0x80,0x60,0x80,0x30,0x00,
0x30,0x00,0x18,0x00,0x0C,0x00,0x06,0x00,
0x06,0x00,0x43,0x00,0x7F,0x80,0x00,0x00,
0x00,0x00,0x00,0x00,0x00,0x00,0x00,0x00,
0x00,0x00,0x00,0x00,0x00,0x00,
/* char7B ('{') */
0x00,0x00,0x03,0x00,0x06,0x00,0x0C,0x00,
0x0C,0x00,0x0C,0x00,0x0C,0x00,0x0C,0x00,
0x0C,0x00,0x18,0x00,0x20,0x00,0x18,0x00,
0x0C,0x00,0x0C,0x00,0x0C,0x00,0x0C,0x00,
0x0C,0x00,0x0C,0x00,0x06,0x00,0x03,0x00,
0x00,0x00,0x00,0x00,0x00,0x00,
/* char7C ('|') */
0x00,0x00,0x40,0x00,0x40,0x00,0x40,0x00,
0x40,0x00,0x40,0x00,0x40,0x00,0x40,0x00,
0x40,0x00,0x40,0x00,0x40,0x00,0x40,0x00,
0x40,0x00,0x40,0x00,0x40,0x00,0x40,0x00,
0x40,0x00,0x40,0x00,0x40,0x00,0x40,0x00,
0x00,0x00,0x00,0x00,0x00,0x00,
/* char7D ('}') */
0x00,0x00,0x30,0x00,0x18,0x00,0x0C,0x00,
0x0C,0x00,0x0C,0x00,0x0C,0x00,0x0C,0x00,
0x0C,0x00,0x06,0x00,0x01,0x00,0x06,0x00,
0x0C,0x00,0x0C,0x00,0x0C,0x00,0x0C,0x00,
0x0C,0x00,0x0C,0x00,0x18,0x00,0x30,0x00,
0x00,0x00,0x00,0x00,0x00,0x00,
/* char7E ('~') */
0x00,0x00,0x00,0x00,0x00,0x00,0x00,0x00,
0x00,0x00,0x00,0x00,0x00,0x00,0x00,0x00,
0x00,0x00,0x81,0xC0,0x8E,0x20,0x70,0x20,
0x00,0x00,0x00,0x00,0x00,0x00,0x00,0x00,
0x00,0x00,0x00,0x00,0x00,0x00,0x00,0x00,
0x00,0x00,0x00,0x00,0x00,0x00,
/* char7F ('') */
0x00,0x00,0x00,0x00,0x00,0x00,0x00,0x00,
0x00,0x00,0x1F,0xF8,0x10,0x08,0x10,0x08,
0x10,0x08,0x10,0x08,0x10,0x08,0x10,0x08,
0x10,0x08,0x10,0x08,0x10,0x08,0x10,0x08,
0x10,0x08,0x10,0x08,0x1F,0xF8,0x00,0x00,
0x00,0x00,0x00,0x00,0x00,0x00,
/* char80 ('Ђ') */
0x00,0x00,0x00,0x00,0x00,0x00,0x00,0x00,
0x00,0x00,0x1F,0xB8,0x06,0x0C,0x06,0x06,
0x06,0x06,0x06,0x06,0x06,0x06,0x06,0x06,
0x07,0x06,0x06,0x8C,0x06,0x78,0x06,0x00,
0x46,0x20,0x66,0x60,0x7F,0xE0,0x00,0x00,
0x00,0x00,0x00,0x00,0x00,0x00,
/* char81 ('Ѓ') */
0x00,0x00,0x00,0x00,0x00,0x00,0x00,0x00,
0x00,0x00,0xFC,0x00,0x30,0x00,0x30,0x00,
0x30,0x00,0x30,0x00,0x30,0x00,0x30,0x00,
0x30,0x00,0x30,0x00,0x30,0x00,0x30,0x00,
0x30,0x20,0x30,0x60,0xFF,0xE0,0x00,0x00,
0x04,0x00,0x06,0x00,0x03,0x00,
/* char82 ('‚') */
0x00,0x00,0x00,0x00,0x20,0x00,0x10,0x00,
0x08,0x00,0x38,0x00,0x30,0x00,0x00,0x00,
0x00,0x00,0x00,0x00,0x00,0x00,0x00,0x00,
0x00,0x00,0x00,0x00,0x00,0x00,0x00,0x00,
0x00,0x00,0x00,0x00,0x00,0x00,0x00,0x00,
0x00,0x00,0x00,0x00,0x00,0x00,
/* char83 ('ѓ') */
0x00,0x00,0x00,0x00,0x00,0x00,0x00,0x00,
0x00,0x00,0x78,0x00,0x30,0x00,0x30,0x00,
0x30,0x00,0x30,0x00,0x30,0x00,0x30,0x00,
0x30,0x80,0x31,0x80,0x7F,0x00,0x00,0x00,
0x08,0x00,0x0C,0x00,0x06,0x00,0x00,0x00,
0x00,0x00,0x00,0x00,0x00,0x00,
/* char84 ('„') */
0x00,0x00,0x00,0x00,0x42,0x00,0x21,0x00,
0x21,0x00,0xE7,0x00,0xC6,0x00,0x00,0x00,
0x00,0x00,0x00,0x00,0x00,0x00,0x00,0x00,
0x00,0x00,0x00,0x00,0x00,0x00,0x00,0x00,
0x00,0x00,0x00,0x00,0x00,0x00,0x00,0x00,
0x00,0x00,0x00,0x00,0x00,0x00,
/* char85 ('…') */
0x00,0x00,0x00,0x00,0x00,0x00,0x00,0x00,
0x00,0x00,0x30,0x60,0x30,0x60,0x00,0x00,
0x00,0x00,0x00,0x00,0x00,0x00,0x00,0x00,
0x00,0x00,0x00,0x00,0x00,0x00,0x00,0x00,
0x00,0x00,0x00,0x00,0x00,0x00,0x00,0x00,
0x00,0x00,0x00,0x00,0x00,0x00,
/* char86 ('†') */
0x00,0x00,0x04,0x00,0x04,0x00,0x04,0x00,
0x04,0x00,0x04,0x00,0x04,0x00,0x04,0x00,
0x04,0x00,0x04,0x00,0x04,0x00,0x04,0x00,
0x04,0x00,0x04,0x00,0x04,0x00,0x7F,0xC0,
0x04,0x00,0x04,0x00,0x04,0x00,0x04,0x00,
0x00,0x00,0x00,0x00,0x00,0x00,
/* char87 ('‡') */
0x04,0x00,0x04,0x00,0x04,0x00,0x04,0x00,
0x3F,0x80,0x04,0x00,0x04,0x00,0x04,0x00,
0x04,0x00,0x04,0x00,0x04,0x00,0x04,0x00,
0x04,0x00,0x04,0x00,0x04,0x00,0x3F,0x80,
0x04,0x00,0x04,0x00,0x04,0x00,0x04,0x00,
0x00,0x00,0x00,0x00,0x00,0x00,
/* char88 ('€') */
0x00,0x00,0x00,0x00,0x00,0x00,0x00,0x00,
0x00,0x00,0x07,0xC0,0x0C,0x60,0x18,0x00,
0x10,0x00,0x30,0x00,0x30,0x00,0xFF,0x80,
0x30,0x00,0xFF,0xC0,0x30,0x00,0x10,0x00,
0x18,0x00,0x0C,0x20,0x03,0xE0,0x00,0x00,
0x00,0x00,0x00,0x00,0x00,0x00,
/* char89 ('‰') */
0x00,0x00,0x00,0x00,0x00,0x00,0x00,0x00,
0x00,0x00,0x20,0x70,0x10,0xD8,0x11,0x8D,
0x09,0x8D,0x05,0x8D,0x03,0x8D,0x3A,0xD8,
0x6D,0x70,0xC6,0x80,0xC6,0x40,0xC6,0x40,
0xC6,0x20,0x6C,0x10,0x38,0x10,0x00,0x00,
0x00,0x00,0x00,0x00,0x00,0x00,
/* char8A ('Љ') */
0x00,0x00,0x00,0x00,0x00,0x00,0x00,0x00,
0x00,0x00,0xE1,0xFE,0xF0,0x63,0x90,0x61,
0x08,0x61,0x08,0x61,0x08,0x61,0x08,0x63,
0x08,0x7E,0x08,0x60,0x08,0x60,0x08,0x60,
0x08,0x60,0x08,0x60,0x3F,0xF8,0x00,0x00,
0x00,0x00,0x00,0x00,0x00,0x00,
/* char8B ('‹') */
0x00,0x00,0x00,0x00,0x00,0x00,0x00,0x00,
0x00,0x00,0x04,0x00,0x08,0x00,0x18,0x00,
0x30,0x00,0x60,0x00,0x60,0x00,0x30,0x00,
0x10,0x00,0x08,0x00,0x04,0x00,0x00,0x00,
0x00,0x00,0x00,0x00,0x00,0x00,0x00,0x00,
0x00,0x00,0x00,0x00,0x00,0x00,
/* char8C ('Њ') */
0x00,0x00,0x00,0x00,0x00,0x00,0x00,0x00,
0x00,0x00,0xFD,0xFE,0x30,0x63,0x30,0x61,
0x30,0x61,0x30,0x61,0x30,0x61,0x30,0x63,
0x3F,0xFE,0x30,0x60,0x30,0x60,0x30,0x60,
0x30,0x60,0x30,0x60,0xFD,0xF8,0x00,0x00,
0x00,0x00,0x00,0x00,0x00,0x00,
/* char8D ('Ќ') */
0x00,0x00,0x00,0x00,0x00,0x00,0x00,0x00,
0x00,0x00,0xFC,0x38,0x30,0x60,0x30,0xC0,
0x30,0xC0,0x31,0x80,0x33,0x00,0x36,0x00,
0x3E,0x00,0x33,0x00,0x31,0x00,0x30,0x80,
0x30,0x80,0x30,0x58,0xFC,0x38,0x00,0x00,
0x02,0x00,0x03,0x00,0x01,0x80,
/* char8E ('Ћ') */
0x00,0x00,0x00,0x00,0x00,0x00,0x00,0x00,
0x00,0x00,0x1F,0xBF,0x06,0x0C,0x06,0x0C,
0x06,0x0C,0x06,0x0C,0x06,0x0C,0x06,0x0C,
0x07,0x0C,0x06,0x9C,0x06,0x78,0x06,0x00,
0x46,0x20,0x66,0x60,0x7F,0xE0,0x00,0x00,
0x00,0x00,0x00,0x00,0x00,0x00,
/* char8F ('Џ') */
0x00,0x00,0x01,0x00,0x01,0x00,0x01,0x00,
0x03,0x80,0xFF,0xFE,0x30,0x18,0x30,0x18,
0x30,0x18,0x30,0x18,0x30,0x18,0x30,0x18,
0x30,0x18,0x30,0x18,0x30,0x18,0x30,0x18,
0x30,0x18,0x30,0x18,0xFC,0x7E,0x00,0x00,
0x00,0x00,0x00,0x00,0x00,0x00,
/* char90 ('ђ') */
0x00,0x00,0x0C,0x00,0x03,0x00,0x01,0x80,
0x01,0x80,0x78,0x80,0x30,0xC0,0x30,0xC0,
0x30,0xC0,0x30,0xC0,0x30,0xC0,0x30,0xC0,
0x30,0xC0,0x39,0x80,0x37,0x00,0x30,0x00,
0x30,0x00,0xFF,0x80,0x30,0x00,0xF0,0x00,
0x00,0x00,0x00,0x00,0x00,0x00,
/* char91 ('‘') */
0x00,0x00,0x00,0x00,0x00,0x00,0x00,0x00,
0x00,0x00,0x00,0x00,0x00,0x00,0x00,0x00,
0x00,0x00,0x00,0x00,0x00,0x00,0x00,0x00,
0x00,0x00,0x00,0x00,0x18,0x00,0x38,0x00,
0x20,0x00,0x30,0x00,0x08,0x00,0x00,0x00,
0x00,0x00,0x00,0x00,0x00,0x00,
/* char92 ('’') */
0x00,0x00,0x00,0x00,0x00,0x00,0x00,0x00,
0x00,0x00,0x00,0x00,0x00,0x00,0x00,0x00,
0x00,0x00,0x00,0x00,0x00,0x00,0x00,0x00,
0x00,0x00,0x00,0x00,0x30,0x00,0x08,0x00,
0x08,0x00,0x38,0x00,0x30,0x00,0x00,0x00,
0x00,0x00,0x00,0x00,0x00,0x00,
/* char93 ('“') */
0x00,0x00,0x00,0x00,0x00,0x00,0x00,0x00,
0x00,0x00,0x00,0x00,0x00,0x00,0x00,0x00,
0x00,0x00,0x00,0x00,0x00,0x00,0x00,0x00,
0x00,0x00,0x00,0x00,0x63,0x00,0xE7,0x00,
0x84,0x00,0x84,0x00,0x42,0x00,0x00,0x00,
0x00,0x00,0x00,0x00,0x00,0x00,
/* char94 ('”') */
0x00,0x00,0x00,0x00,0x00,0x00,0x00,0x00,
0x00,0x00,0x00,0x00,0x00,0x00,0x00,0x00,
0x00,0x00,0x00,0x00,0x00,0x00,0x00,0x00,
0x00,0x00,0x00,0x00,0x42,0x00,0x21,0x00,
0x21,0x00,0xE7,0x00,0xC6,0x00,0x00,0x00,
0x00,0x00,0x00,0x00,0x00,0x00,
/* char95 ('•') */
0x00,0x00,0x00,0x00,0x00,0x00,0x00,0x00,
0x00,0x00,0x00,0x00,0x00,0x00,0x00,0x00,
0x00,0x00,0x00,0x00,0x38,0x00,0x7C,0x00,
0x7C,0x00,0x7C,0x00,0x38,0x00,0x00,0x00,
0x00,0x00,0x00,0x00,0x00,0x00,0x00,0x00,
0x00,0x00,0x00,0x00,0x00,0x00,
/* char96 ('–') */
0x00,0x00,0x00,0x00,0x00,0x00,0x00,0x00,
0x00,0x00,0x00,0x00,0x00,0x00,0x00,0x00,
0x00,0x00,0x00,0x00,0xFF,0xE0,0x00,0x00,
0x00,0x00,0x00,0x00,0x00,0x00,0x00,0x00,
0x00,0x00,0x00,0x00,0x00,0x00,0x00,0x00,
0x00,0x00,0x00,0x00,0x00,0x00,
/* char97 ('—') */
0x00,0x00,0x00,0x00,0x00,0x00,0x00,0x00,
0x00,0x00,0x00,0x00,0x00,0x00,0x00,0x00,
0x00,0x00,0x00,0x00,0xFF,0xFF,0x00,0x00,
0x00,0x00,0x00,0x00,0x00,0x00,0x00,0x00,
0x00,0x00,0x00,0x00,0x00,0x00,0x00,0x00,
0x00,0x00,0x00,0x00,0x00,0x00,
/* char98 ('') */
0x00,0x00,0x00,0x00,0x00,0x00,0x00,0x00,
0x00,0x00,0x1F,0xF8,0x10,0x08,0x10,0x08,
0x10,0x08,0x10,0x08,0x10,0x08,0x10,0x08,
0x10,0x08,0x10,0x08,0x10,0x08,0x10,0x08,
0x10,0x08,0x10,0x08,0x1F,0xF8,0x00,0x00,
0x00,0x00,0x00,0x00,0x00,0x00,
/* char99 ('™') */
0x00,0x00,0x00,0x00,0x00,0x00,0x00,0x00,
0x00,0x00,0x00,0x00,0x00,0x00,0x00,0x00,
0x00,0x00,0x00,0x00,0x00,0x00,0x1E,0x39,
0x0C,0x13,0x0C,0x13,0x0C,0x16,0x0C,0x16,
0x0C,0x1C,0x4C,0x9C,0x7F,0xB8,0x00,0x00,
0x00,0x00,0x00,0x00,0x00,0x00,
/* char9A ('љ') */
0x00,0x00,0x00,0x00,0x00,0x00,0x00,0x00,
0x00,0x00,0xE3,0xF8,0x91,0x8C,0x11,0x8C,
0x11,0x8C,0x11,0x8C,0x11,0xF8,0x11,0x80,
0x11,0x80,0x11,0x80,0x3F,0xC0,0x00,0x00,
0x00,0x00,0x00,0x00,0x00,0x00,0x00,0x00,
0x00,0x00,0x00,0x00,0x00,0x00,
/* char9B ('›') */
0x00,0x00,0x00,0x00,0x00,0x00,0x00,0x00,
0x00,0x00,0x40,0x00,0x20,0x00,0x10,0x00,
0x18,0x00,0x0C,0x00,0x0C,0x00,0x18,0x00,
0x30,0x00,0x20,0x00,0x40,0x00,0x00,0x00,
0x00,0x00,0x00,0x00,0x00,0x00,0x00,0x00,
0x00,0x00,0x00,0x00,0x00,0x00,
/* char9C ('њ') */
0x00,0x00,0x00,0x00,0x00,0x00,0x00,0x00,
0x00,0x00,0xF3,0xF8,0x61,0x8C,0x61,0x8C,
0x61,0x8C,0x61,0x8C,0x7F,0xF8,0x61,0x80,
0x61,0x80,0x61,0x80,0xF3,0xC0,0x00,0x00,
0x00,0x00,0x00,0x00,0x00,0x00,0x00,0x00,
0x00,0x00,0x00,0x00,0x00,0x00,
/* char9D ('ќ') */
0x00,0x00,0x00,0x00,0x00,0x00,0x00,0x00,
0x00,0x00,0xF1,0xC0,0x63,0x00,0x63,0x00,
0x66,0x00,0x6C,0x00,0x78,0x00,0x64,0x00,
0x62,0x00,0x62,0xC0,0xF1,0xC0,0x00,0x00,
0x08,0x00,0x0C,0x00,0x06,0x00,0x00,0x00,
0x00,0x00,0x00,0x00,0x00,0x00,
/* char9E ('ћ') */
0x00,0x00,0x00,0x00,0x00,0x00,0x00,0x00,
0x00,0x00,0xF3,0xC0,0x61,0x80,0x61,0x80,
0x61,0x80,0x61,0x80,0x61,0x80,0x61,0x80,
0x61,0x80,0x79,0x80,0x67,0x00,0x60,0x00,
0x60,0x00,0xFF,0x00,0x60,0x00,0xE0,0x00,
0x00,0x00,0x00,0x00,0x00,0x00,
/* char9F ('џ') */
0x00,0x00,0x00,0x00,0x04,0x00,0x04,0x00,
0x0E,0x00,0xFF,0xE0,0x60,0xC0,0x60,0xC0,
0x60,0xC0,0x60,0xC0,0x60,0xC0,0x60,0xC0,
0x60,0xC0,0x60,0xC0,0xF1,0xE0,0x00,0x00,
0x00,0x00,0x00,0x00,0x00,0x00,0x00,0x00,
0x00,0x00,0x00,0x00,0x00,0x00,
/* charA0 (' ') */
0x00,0x00,0x00,0x00,0x00,0x00,0x00,0x00,
0x00,0x00,0x00,0x00,0x00,0x00,0x00,0x00,
0x00,0x00,0x00,0x00,0x00,0x00,0x00,0x00,
0x00,0x00,0x00,0x00,0x00,0x00,0x00,0x00,
0x00,0x00,0x00,0x00,0x00,0x00,0x00,0x00,
0x00,0x00,0x00,0x00,0x00,0x00,
/* charA1 ('Ў') */
0x00,0x00,0x00,0x00,0x00,0x00,0x00,0x00,
0x00,0x00,0x1E,0x00,0x19,0x00,0x01,0x00,
0x00,0x80,0x01,0x80,0x03,0x40,0x03,0x40,
0x06,0x40,0x0C,0x20,0x0C,0x20,0x18,0x20,
0x18,0x10,0x30,0x18,0xFC,0x3C,0x00,0x00,
0x0F,0xC0,0x1C,0xE0,0x18,0x60,
/* charA2 ('ў') */
0x00,0x00,0x70,0x00,0x68,0x00,0x04,0x00,
0x04,0x00,0x04,0x00,0x06,0x00,0x06,0x00,
0x0D,0x00,0x0D,0x00,0x0D,0x80,0x18,0x80,
0x18,0x80,0x30,0x40,0x78,0xE0,0x00,0x00,
0x0F,0x80,0x18,0xC0,0x18,0xC0,0x00,0x00,
0x00,0x00,0x00,0x00,0x00,0x00,
/* charA3 ('Ј') */
0x00,0x00,0x00,0x00,0x00,0x00,0x00,0x00,
0x00,0x00,0x70,0x00,0xE8,0x00,0xCC,0x00,
0x0C,0x00,0x0C,0x00,0x0C,0x00,0x0C,0x00,
0x0C,0x00,0x0C,0x00,0x0C,0x00,0x0C,0x00,
0x0C,0x00,0x0C,0x00,0x3F,0x00,0x00,0x00,
0x00,0x00,0x00,0x00,0x00,0x00,
/* charA4 ('¤') */
0x00,0x00,0x00,0x00,0x00,0x00,0x00,0x00,
0x00,0x00,0x00,0x00,0x00,0x00,0x5E,0x80,
0x61,0x00,0x40,0x80,0x80,0x40,0x80,0x40,
0x80,0x40,0x80,0x40,0x40,0x80,0x21,0x00,
0x5E,0x80,0x00,0x00,0x00,0x00,0x00,0x00,
0x00,0x00,0x00,0x00,0x00,0x00,
/* charA5 ('Ґ') */
0x00,0x00,0x00,0x00,0x00,0x00,0x00,0x00,
0x00,0x00,0xFC,0x00,0x30,0x00,0x30,0x00,
0x30,0x00,0x30,0x00,0x30,0x00,0x30,0x00,
0x30,0x00,0x30,0x00,0x30,0x00,0x30,0x00,
0x30,0x00,0x30,0x00,0xFF,0x80,0x01,0x80,
0x00,0x80,0x00,0x80,0x00,0x00,
/* charA6 ('¦') */
0x00,0x00,0x40,0x00,0x40,0x00,0x40,0x00,
0x40,0x00,0x40,0x00,0x40,0x00,0x40,0x00,
0x40,0x00,0x00,0x00,0x00,0x00,0x00,0x00,
0x00,0x00,0x40,0x00,0x40,0x00,0x40,0x00,
0x40,0x00,0x40,0x00,0x40,0x00,0x40,0x00,
0x00,0x00,0x00,0x00,0x00,0x00,
/* charA7 ('§') */
0x00,0x00,0x1E,0x00,0x31,0x00,0x31,0x00,
0x03,0x00,0x06,0x00,0x0E,0x00,0x19,0x00,
0x10,0x80,0x20,0x80,0x21,0x80,0x21,0x00,
0x13,0x00,0x0E,0x00,0x0C,0x00,0x18,0x00,
0x11,0x80,0x11,0x80,0x0F,0x00,0x00,0x00,
0x00,0x00,0x00,0x00,0x00,0x00,
/* charA8 ('Ё') */
0x00,0x00,0x00,0x00,0x00,0x00,0x00,0x00,
0x00,0x00,0xFF,0xF0,0x30,0x30,0x30,0x10,
0x30,0x08,0x30,0x00,0x30,0x40,0x30,0x40,
0x3F,0xC0,0x30,0x40,0x30,0x40,0x30,0x00,
0x30,0x10,0x30,0x30,0xFF,0xF0,0x00,0x00,
0x0D,0x80,0x0D,0x80,0x00,0x00,
/* charA9 ('©') */
0x00,0x00,0x00,0x00,0x00,0x00,0x00,0x00,
0x00,0x00,0x07,0xE0,0x0C,0x30,0x10,0x08,
0x23,0xC4,0x66,0x36,0x4C,0x02,0x4C,0x02,
0x4C,0x02,0x4C,0x02,0x66,0x16,0x23,0xF4,
0x10,0x08,0x0C,0x30,0x07,0xE0,0x00,0x00,
0x00,0x00,0x00,0x00,0x00,0x00,
/* charAA ('Є') */
0x00,0x00,0x00,0x00,0x00,0x00,0x00,0x00,
0x00,0x00,0x07,0xE0,0x0C,0x30,0x18,0x08,
0x30,0x04,0x60,0x00,0x60,0x00,0x60,0x00,
0x7F,0x00,0x60,0x00,0x60,0x08,0x30,0x08,
0x10,0x18,0x0C,0x78,0x07,0xC8,0x00,0x00,
0x00,0x00,0x00,0x00,0x00,0x00,
/* charAB ('«') */
0x00,0x00,0x00,0x00,0x00,0x00,0x00,0x00,
0x00,0x00,0x08,0x40,0x10,0x80,0x31,0x80,
0x63,0x00,0xC6,0x00,0xC6,0x00,0x63,0x00,
0x21,0x00,0x10,0x80,0x08,0x40,0x00,0x00,
0x00,0x00,0x00,0x00,0x00,0x00,0x00,0x00,
0x00,0x00,0x00,0x00,0x00,0x00,
/* charAC ('¬') */
0x00,0x00,0x00,0x00,0x00,0x00,0x00,0x00,
0x00,0x00,0x00,0x00,0x00,0x00,0x00,0x00,
0x00,0x00,0x00,0x00,0x00,0x20,0x00,0x20,
0x00,0x20,0xFF,0xE0,0x00,0x00,0x00,0x00,
0x00,0x00,0x00,0x00,0x00,0x00,0x00,0x00,
0x00,0x00,0x00,0x00,0x00,0x00,
/* charAD ('­') */
0x00,0x00,0x00,0x00,0x00,0x00,0x00,0x00,
0x00,0x00,0x00,0x00,0x00,0x00,0x00,0x00,
0x00,0x00,0x7C,0x00,0x7C,0x00,0x00,0x00,
0x00,0x00,0x00,0x00,0x00,0x00,0x00,0x00,
0x00,0x00,0x00,0x00,0x00,0x00,0x00,0x00,
0x00,0x00,0x00,0x00,0x00,0x00,
/* charAE ('®') */
0x00,0x00,0x00,0x00,0x00,0x00,0x00,0x00,
0x00,0x00,0x07,0xE0,0x0C,0x30,0x10,0x08,
0x2F,0x34,0x66,0x66,0x46,0xC2,0x46,0x82,
0x47,0x82,0x46,0x62,0x66,0x66,0x2F,0xC4,
0x10,0x08,0x0C,0x30,0x07,0xE0,0x00,0x00,
0x00,0x00,0x00,0x00,0x00,0x00,
/* charAF ('Ї') */
0x00,0x00,0x00,0x00,0x00,0x00,0x00,0x00,
0x00,0x00,0xFC,0x00,0x30,0x00,0x30,0x00,
0x30,0x00,0x30,0x00,0x30,0x00,0x30,0x00,
0x30,0x00,0x30,0x00,0x30,0x00,0x30,0x00,
0x30,0x00,0x30,0x00,0xFC,0x00,0x00,0x00,
0x6C,0x00,0x6C,0x00,0x00,0x00,
/* charB0 ('°') */
0x00,0x00,0x00,0x00,0x00,0x00,0x00,0x00,
0x00,0x00,0x00,0x00,0x00,0x00,0x00,0x00,
0x00,0x00,0x00,0x00,0x00,0x00,0x00,0x00,
0x00,0x00,0x3C,0x00,0x66,0x00,0x42,0x00,
0x42,0x00,0x66,0x00,0x3C,0x00,0x00,0x00,
0x00,0x00,0x00,0x00,0x00,0x00,
/* charB1 ('±') */
0x00,0x00,0x00,0x00,0x00,0x00,0x00,0x00,
0x00,0x00,0x00,0x00,0x00,0x00,0xFF,0xE0,
0x04,0x00,0x04,0x00,0x04,0x00,0x04,0x00,
0xFF,0xE0,0x04,0x00,0x04,0x00,0x04,0x00,
0x04,0x00,0x04,0x00,0x00,0x00,0x00,0x00,
0x00,0x00,0x00,0x00,0x00,0x00,
/* charB2 ('І') */
0x00,0x00,0x00,0x00,0x00,0x00,0x00,0x00,
0x00,0x00,0xFC,0x00,0x30,0x00,0x30,0x00,
0x30,0x00,0x30,0x00,0x30,0x00,0x30,0x00,
0x30,0x00,0x30,0x00,0x30,0x00,0x30,0x00,
0x30,0x00,0x30,0x00,0xFC,0x00,0x00,0x00,
0x00,0x00,0x00,0x00,0x00,0x00,
/* charB3 ('і') */
0x00,0x00,0x00,0x00,0x00,0x00,0x00,0x00,
0x00,0x00,0x78,0x00,0x30,0x00,0x30,0x00,
0x30,0x00,0x30,0x00,0x30,0x00,0x30,0x00,
0x30,0x00,0x70,0x00,0x30,0x00,0x00,0x00,
0x00,0x00,0x00,0x00,0x30,0x00,0x30,0x00,
0x00,0x00,0x00,0x00,0x00,0x00,
/* charB4 ('ґ') */
0x00,0x00,0x00,0x00,0x00,0x00,0x00,0x00,
0x00,0x00,0x78,0x00,0x30,0x00,0x30,0x00,
0x30,0x00,0x30,0x00,0x30,0x00,0x30,0x00,
0x30,0x00,0x30,0x00,0x7E,0x00,0x02,0x00,
0x02,0x00,0x00,0x00,0x00,0x00,0x00,0x00,
0x00,0x00,0x00,0x00,0x00,0x00,
/* charB5 ('µ') */
0x00,0x00,0x60,0x00,0x60,0x00,0x60,0x00,
0x20,0x00,0x3E,0x60,0x31,0xD0,0x30,0xC0,
0x30,0xC0,0x30,0xC0,0x30,0xC0,0x30,0xC0,
0x30,0xC0,0x30,0xC0,0x30,0xC0,0x00,0x00,
0x00,0x00,0x00,0x00,0x00,0x00,0x00,0x00,
0x00,0x00,0x00,0x00,0x00,0x00,
/* charB6 ('¶') */
0x04,0x80,0x04,0x80,0x04,0x80,0x04,0x80,
0x04,0x80,0x04,0x80,0x04,0x80,0x04,0x80,
0x04,0x80,0x04,0x80,0x04,0x80,0x3C,0x80,
0x7C,0x80,0xFC,0x80,0xFC,0x80,0xFC,0x80,
0xFC,0x80,0x7C,0x80,0x3F,0xC0,0x00,0x00,
0x00,0x00,0x00,0x00,0x00,0x00,
/* charB7 ('·') */
0x00,0x00,0x00,0x00,0x00,0x00,0x00,0x00,
0x00,0x00,0x00,0x00,0x00,0x00,0x00,0x00,
0x00,0x00,0x00,0x00,0x00,0x00,0x60,0x00,
0x60,0x00,0x00,0x00,0x00,0x00,0x00,0x00,
0x00,0x00,0x00,0x00,0x00,0x00,0x00,0x00,
0x00,0x00,0x00,0x00,0x00,0x00,
/* charB8 ('ё') */
0x00,0x00,0x00,0x00,0x00,0x00,0x00,0x00,
0x00,0x00,0x1E,0x00,0x3F,0x00,0x70,0x80,
0x60,0x00,0x60,0x00,0x60,0x00,0x7F,0x80,
0x61,0x80,0x33,0x00,0x1E,0x00,0x00,0x00,
0x1B,0x00,0x1B,0x00,0x00,0x00,0x00,0x00,
0x00,0x00,0x00,0x00,0x00,0x00,
/* charB9 ('№') */
0x00,0x00,0x00,0x00,0x00,0x00,0x00,0x00,
0x00,0x00,0x70,0x13,0x68,0x10,0x08,0x30,
0x08,0x71,0x08,0x73,0x08,0xD3,0x08,0xD3,
0x09,0x93,0x09,0x91,0x0B,0x10,0x0E,0x10,
0x0E,0x10,0x0C,0x16,0x3C,0x0E,0x00,0x00,
0x00,0x00,0x00,0x00,0x00,0x00,
/* charBA ('є') */
0x00,0x00,0x00,0x00,0x00,0x00,0x00,0x00,
0x00,0x00,0x1F,0x00,0x31,0x80,0x20,0x00,
0x60,0x00,0x60,0x00,0x7C,0x00,0x60,0x00,
0x61,0x00,0x33,0x00,0x1D,0x00,0x00,0x00,
0x00,0x00,0x00,0x00,0x00,0x00,0x00,0x00,
0x00,0x00,0x00,0x00,0x00,0x00,
/* charBB ('»') */
0x00,0x00,0x00,0x00,0x00,0x00,0x00,0x00,
0x00,0x00,0x84,0x00,0x42,0x00,0x21,0x00,
0x31,0x80,0x18,0xC0,0x18,0xC0,0x31,0x80,
0x63,0x00,0x42,0x00,0x84,0x00,0x00,0x00,
0x00,0x00,0x00,0x00,0x00,0x00,0x00,0x00,
0x00,0x00,0x00,0x00,0x00,0x00,
/* charBC ('ј') */
0x00,0x00,0xF0,0x00,0xC8,0x00,0x0C,0x00,
0x0C,0x00,0x0C,0x00,0x0C,0x00,0x0C,0x00,
0x0C,0x00,0x0C,0x00,0x0C,0x00,0x0C,0x00,
0x0C,0x00,0x1C,0x00,0x0C,0x00,0x00,0x00,
0x00,0x00,0x00,0x00,0x0C,0x00,0x0C,0x00,
0x00,0x00,0x00,0x00,0x00,0x00,
/* charBD ('Ѕ') */
0x00,0x00,0x00,0x00,0x00,0x00,0x00,0x00,
0x00,0x00,0x4F,0x00,0x71,0x80,0x60,0xC0,
0x40,0xC0,0x41,0xC0,0x03,0x80,0x07,0x00,
0x1E,0x00,0x38,0x00,0x70,0x80,0x60,0x80,
0x61,0x80,0x33,0x80,0x1C,0x80,0x00,0x00,
0x00,0x00,0x00,0x00,0x00,0x00,
/* charBE ('ѕ') */
0x00,0x00,0x00,0x00,0x00,0x00,0x00,0x00,
0x00,0x00,0x5C,0x00,0x62,0x00,0x42,0x00,
0x06,0x00,0x3E,0x00,0x7C,0x00,0x60,0x00,
0x42,0x00,0x46,0x00,0x3A,0x00,0x00,0x00,
0x00,0x00,0x00,0x00,0x00,0x00,0x00,0x00,
0x00,0x00,0x00,0x00,0x00,0x00,
/* charBF ('ї') */
0x00,0x00,0x00,0x00,0x00,0x00,0x00,0x00,
0x00,0x00,0x78,0x00,0x30,0x00,0x30,0x00,
0x30,0x00,0x30,0x00,0x30,0x00,0x30,0x00,
0x30,0x00,0x70,0x00,0x30,0x00,0x00,0x00,
0x00,0x00,0xD8,0x00,0xD8,0x00,0x00,0x00,
0x00,0x00,0x00,0x00,0x00,0x00,
/* charC0 ('А') */
0x00,0x00,0x00,0x00,0x00,0x00,0x00,0x00,
0x00,0x00,0xF0,0x7C,0x60,0x38,0x20,0x30,
0x20,0x30,0x10,0x60,0x1F,0xE0,0x08,0x60,
0x08,0xC0,0x04,0xC0,0x04,0xC0,0x05,0x80,
0x03,0x80,0x03,0x00,0x01,0x00,0x00,0x00,
0x00,0x00,0x00,0x00,0x00,0x00,
/* charC1 ('Б') */
0x00,0x00,0x00,0x00,0x00,0x00,0x00,0x00,
0x00,0x00,0xFF,0x80,0x30,0xC0,0x30,0x60,
0x30,0x60,0x30,0x60,0x30,0x60,0x30,0xC0,
0x3F,0x80,0x30,0x00,0x30,0x00,0x30,0x00,
0x30,0x40,0x30,0xC0,0xFF,0xC0,0x00,0x00,
0x00,0x00,0x00,0x00,0x00,0x00,
/* charC2 ('В') */
0x00,0x00,0x00,0x00,0x00,0x00,0x00,0x00,
0x00,0x00,0xFF,0xE0,0x30,0x30,0x30,0x18,
0x30,0x18,0x30,0x18,0x30,0x38,0x30,0x70,
0x3F,0xC0,0x30,0x60,0x30,0x30,0x30,0x30,
0x30,0x30,0x30,0x60,0xFF,0xC0,0x00,0x00,
0x00,0x00,0x00,0x00,0x00,0x00,
/* charC3 ('Г') */
0x00,0x00,0x00,0x00,0x00,0x00,0x00,0x00,
0x00,0x00,0xFC,0x00,0x30,0x00,0x30,0x00,
0x30,0x00,0x30,0x00,0x30,0x00,0x30,0x00,
0x30,0x00,0x30,0x00,0x30,0x00,0x30,0x00,
0x30,0x20,0x30,0x60,0xFF,0xE0,0x00,0x00,
0x00,0x00,0x00,0x00,0x00,0x00,
/* charC4 ('Д') */
0x00,0x00,0x80,0x04,0x80,0x04,0xC0,0x0C,
0xE0,0x1C,0xFF,0xFC,0x20,0x30,0x10,0x30,
0x08,0x30,0x08,0x30,0x08,0x30,0x08,0x30,
0x04,0x30,0x04,0x30,0x04,0x30,0x04,0x30,
0x04,0x30,0x04,0x30,0x1F,0xFC,0x00,0x00,
0x00,0x00,0x00,0x00,0x00,0x00,
/* charC5 ('Е') */
0x00,0x00,0x00,0x00,0x00,0x00,0x00,0x00,
0x00,0x00,0xFF,0xF0,0x30,0x30,0x30,0x10,
0x30,0x08,0x30,0x00,0x30,0x40,0x30,0x40,
0x3F,0xC0,0x30,0x40,0x30,0x40,0x30,0x00,
0x30,0x10,0x30,0x30,0xFF,0xF0,0x00,0x00,
0x00,0x00,0x00,0x00,0x00,0x00,
/* charC6 ('Ж') */
0x00,0x00,0x00,0x00,0x00,0x00,0x00,0x00,
0x00,0x00,0x79,0xF9,0x18,0x61,0x0C,0x63,
0x0C,0x63,0x06,0x66,0x06,0x66,0x03,0x6C,
0x01,0xF8,0x02,0x64,0x04,0x62,0x04,0x62,
0x04,0x62,0x68,0x61,0x71,0xF8,0x00,0x00,
0x00,0x00,0x00,0x00,0x00,0x00,
/* charC7 ('З') */
0x00,0x00,0x00,0x00,0x00,0x00,0x00,0x00,
0x00,0x00,0x1F,0x00,0x31,0x80,0x40,0xC0,
0x00,0xC0,0x00,0xC0,0x00,0xC0,0x03,0x80,
0x1E,0x00,0x03,0x80,0x00,0xC0,0x40,0xC0,
0x60,0xC0,0x71,0x80,0x4F,0x00,0x00,0x00,
0x00,0x00,0x00,0x00,0x00,0x00,
/* charC8 ('И') */
0x00,0x00,0x00,0x00,0x00,0x00,0x00,0x00,
0x00,0x00,0xFC,0x7E,0x30,0x18,0x30,0x18,
0x38,0x18,0x34,0x18,0x32,0x18,0x31,0x18,
0x31,0x18,0x30,0x98,0x30,0x58,0x30,0x38,
0x30,0x18,0x30,0x18,0xFC,0x7E,0x00,0x00,
0x00,0x00,0x00,0x00,0x00,0x00,
/* charC9 ('Й') */
0x00,0x00,0x00,0x00,0x00,0x00,0x00,0x00,
0x00,0x00,0xFC,0x7E,0x30,0x18,0x30,0x18,
0x38,0x18,0x34,0x18,0x32,0x18,0x31,0x18,
0x31,0x18,0x30,0x98,0x30,0x58,0x30,0x38,
0x30,0x18,0x30,0x18,0xFC,0x7E,0x00,0x00,
0x07,0xC0,0x1C,0x70,0x18,0x30,
/* charCA ('К') */
0x00,0x00,0x00,0x00,0x00,0x00,0x00,0x00,
0x00,0x00,0xFC,0x38,0x30,0x60,0x30,0xC0,
0x30,0xC0,0x31,0x80,0x33,0x00,0x36,0x00,
0x3E,0x00,0x33,0x00,0x31,0x00,0x30,0x80,
0x30,0x80,0x30,0x58,0xFC,0x38,0x00,0x00,
0x00,0x00,0x00,0x00,0x00,0x00,
/* charCB ('Л') */
0x00,0x00,0x00,0x00,0x00,0x00,0x00,0x00,
0x00,0x00,0x70,0xFC,0x78,0x30,0x48,0x30,
0x04,0x30,0x04,0x30,0x04,0x30,0x04,0x30,
0x04,0x30,0x04,0x30,0x04,0x30,0x04,0x30,
0x04,0x30,0x04,0x30,0x1F,0xFC,0x00,0x00,
0x00,0x00,0x00,0x00,0x00,0x00,
/* charCC ('М') */
0x00,0x00,0x00,0x00,0x00,0x00,0x00,0x00,
0x00,0x00,0xF8,0x8F,0x21,0x83,0x21,0xC3,
0x21,0xC3,0x23,0x23,0x23,0x23,0x27,0x13,
0x26,0x13,0x2E,0x0B,0x2C,0x0B,0x2C,0x0B,
0x3C,0x07,0x38,0x07,0xF8,0x03,0x00,0x00,
0x00,0x00,0x00,0x00,0x00,0x00,
/* charCD ('Н') */
0x00,0x00,0x00,0x00,0x00,0x00,0x00,0x00,
0x00,0x00,0xFC,0x7E,0x30,0x18,0x30,0x18,
0x30,0x18,0x30,0x18,0x30,0x18,0x30,0x18,
0x3F,0xF8,0x30,0x18,0x30,0x18,0x30,0x18,
0x30,0x18,0x30,0x18,0xFC,0x7E,0x00,0x00,
0x00,0x00,0x00,0x00,0x00,0x00,
/* charCE ('О') */
0x00,0x00,0x00,0x00,0x00,0x00,0x00,0x00,
0x00,0x00,0x07,0xC0,0x18,0x30,0x30,0x18,
0x30,0x18,0x60,0x0C,0x60,0x0C,0x60,0x0C,
0x60,0x0C,0x60,0x0C,0x60,0x0C,0x30,0x18,
0x30,0x18,0x18,0x30,0x07,0xC0,0x00,0x00,
0x00,0x00,0x00,0x00,0x00,0x00,
/* charCF ('П') */
0x00,0x00,0x00,0x00,0x00,0x00,0x00,0x00,
0x00,0x00,0xFC,0x7E,0x30,0x18,0x30,0x18,
0x30,0x18,0x30,0x18,0x30,0x18,0x30,0x18,
0x30,0x18,0x30,0x18,0x30,0x18,0x30,0x18,
0x30,0x18,0x30,0x18,0xFF,0xFE,0x00,0x00,
0x00,0x00,0x00,0x00,0x00,0x00,
/* charD0 ('Р') */
0x00,0x00,0x00,0x00,0x00,0x00,0x00,0x00,
0x00,0x00,0xFC,0x00,0x30,0x00,0x30,0x00,
0x30,0x00,0x30,0x00,0x30,0x00,0x3F,0x80,
0x30,0xC0,0x30,0x60,0x30,0x60,0x30,0x60,
0x30,0x60,0x30,0xC0,0xFF,0x80,0x00,0x00,
0x00,0x00,0x00,0x00,0x00,0x00,
/* charD1 ('С') */
0x00,0x00,0x00,0x00,0x00,0x00,0x00,0x00,
0x00,0x00,0x07,0xC0,0x1C,0x20,0x30,0x10,
0x30,0x08,0x60,0x00,0x60,0x00,0x60,0x00,
0x60,0x00,0x60,0x00,0x60,0x08,0x30,0x18,
0x10,0x18,0x0C,0x38,0x07,0xC8,0x00,0x00,
0x00,0x00,0x00,0x00,0x00,0x00,
/* charD2 ('Т') */
0x00,0x00,0x00,0x00,0x00,0x00,0x00,0x00,
0x00,0x00,0x1F,0x80,0x06,0x00,0x06,0x00,
0x06,0x00,0x06,0x00,0x06,0x00,0x06,0x00,
0x06,0x00,0x06,0x00,0x06,0x00,0x06,0x00,
0x86,0x10,0xC6,0x30,0xFF,0xF0,0x00,0x00,
0x00,0x00,0x00,0x00,0x00,0x00,
/* charD3 ('У') */
0x00,0x00,0x00,0x00,0x00,0x00,0x00,0x00,
0x00,0x00,0x1E,0x00,0x19,0x00,0x01,0x00,
0x00,0x80,0x01,0x80,0x03,0x40,0x03,0x40,
0x06,0x40,0x0C,0x20,0x0C,0x20,0x18,0x20,
0x18,0x10,0x30,0x18,0xFC,0x3C,0x00,0x00,
0x00,0x00,0x00,0x00,0x00,0x00,
/* charD4 ('Ф') */
0x00,0x00,0x00,0x00,0x00,0x00,0x00,0x00,
0x00,0x00,0x03,0xF0,0x00,0xC0,0x0F,0xF8,
0x18,0xCE,0x30,0xC6,0x60,0xC3,0x60,0xC3,
0x60,0xC3,0x60,0xC3,0x30,0xC6,0x18,0xCE,
0x0F,0xF8,0x00,0xC0,0x03,0xF0,0x00,0x00,
0x00,0x00,0x00,0x00,0x00,0x00,
/* charD5 ('Х') */
0x00,0x00,0x00,0x00,0x00,0x00,0x00,0x00,
0x00,0x00,0xF8,0x7C,0x30,0x38,0x08,0x30,
0x0C,0x60,0x04,0xC0,0x03,0xC0,0x01,0x80,
0x03,0x00,0x07,0x80,0x06,0x40,0x0C,0x20,
0x18,0x30,0x38,0x18,0xFE,0x7C,0x00,0x00,
0x00,0x00,0x00,0x00,0x00,0x00,
/* charD6 ('Ц') */
0x00,0x00,0x00,0x02,0x00,0x02,0x00,0x06,
0x00,0x0E,0xFF,0xF8,0x30,0x18,0x30,0x18,
0x30,0x18,0x30,0x18,0x30,0x18,0x30,0x18,
0x30,0x18,0x30,0x18,0x30,0x18,0x30,0x18,
0x30,0x18,0x30,0x18,0xFC,0x7E,0x00,0x00,
0x00,0x00,0x00,0x00,0x00,0x00,
/* charD7 ('Ч') */
0x00,0x00,0x00,0x00,0x00,0x00,0x00,0x00,
0x00,0x00,0x00,0xFC,0x00,0x30,0x00,0x30,
0x00,0x30,0x00,0x30,0x0F,0xB0,0x18,0x70,
0x30,0x30,0x30,0x30,0x30,0x30,0x30,0x30,
0x30,0x30,0x30,0x30,0xFC,0xFC,0x00,0x00,
0x00,0x00,0x00,0x00,0x00,0x00,
/* charD8 ('Ш') */
0x00,0x00,0x00,0x00,0x00,0x00,0x00,0x00,
0x00,0x00,0xFF,0xFF,0x30,0x30,0x30,0x30,
0x30,0x30,0x30,0x30,0x30,0x30,0x30,0x30,
0x30,0x30,0x30,0x30,0x30,0x30,0x30,0x30,
0x30,0x30,0x30,0x30,0xFC,0xFD,0x00,0x00,
0x00,0x00,0x00,0x00,0x00,0x00,
/* charD9 ('Щ') */
0x00,0x00,0x00,0x00,0x00,0x00,0x00,0x00,
0x00,0x00,0xFF,0xFF,0x30,0x30,0x30,0x30,
0x30,0x30,0x30,0x30,0x30,0x30,0x30,0x30,
0x30,0x30,0x30,0x30,0x30,0x30,0x30,0x30,
0x30,0x30,0x30,0x30,0xFC,0xFD,0x00,0x00,
0x00,0x00,0x00,0x00,0x00,0x00,
/* charDA ('Ъ') */
0x00,0x00,0x00,0x00,0x00,0x00,0x00,0x00,
0x00,0x00,0x1F,0xF0,0x06,0x18,0x06,0x0C,
0x06,0x0C,0x06,0x0C,0x06,0x0C,0x06,0x18,
0x07,0xF0,0x06,0x00,0x06,0x00,0x06,0x00,
0x86,0x00,0xC6,0x00,0xFF,0x80,0x00,0x00,
0x00,0x00,0x00,0x00,0x00,0x00,
/* charDB ('Ы') */
0x00,0x00,0x00,0x00,0x00,0x00,0x00,0x00,
0x00,0x00,0xFF,0x8F,0x30,0xC3,0x30,0x63,
0x30,0x63,0x30,0x63,0x30,0x63,0x30,0xC3,
0x3F,0x83,0x30,0x03,0x30,0x03,0x30,0x03,
0x30,0x03,0x30,0x03,0xFC,0x0F,0x00,0x00,
0x00,0x00,0x00,0x00,0x00,0x00,
/* charDC ('Ь') */
0x00,0x00,0x00,0x00,0x00,0x00,0x00,0x00,
0x00,0x00,0xFF,0x80,0x30,0xC0,0x30,0x60,
0x30,0x60,0x30,0x60,0x30,0x60,0x30,0xC0,
0x3F,0x80,0x30,0x00,0x30,0x00,0x30,0x00,
0x30,0x00,0x30,0x00,0xFC,0x00,0x00,0x00,
0x00,0x00,0x00,0x00,0x00,0x00,
/* charDD ('Э') */
0x00,0x00,0x00,0x00,0x00,0x00,0x00,0x00,
0x00,0x00,0x1F,0x80,0x30,0xC0,0x40,0x60,
0x80,0x30,0x00,0x18,0x00,0x18,0x00,0x18,
0x03,0xF8,0x00,0x18,0x40,0x18,0x40,0x30,
0x60,0x20,0x78,0xC0,0x4F,0x80,0x00,0x00,
0x00,0x00,0x00,0x00,0x00,0x00,
/* charDE ('Ю') */
0x00,0x00,0x00,0x00,0x00,0x00,0x00,0x00,
0x00,0x00,0xFC,0x1F,0x30,0x30,0x30,0x40,
0x30,0xC0,0x31,0x80,0x31,0x80,0x31,0x80,
0x3F,0x80,0x31,0x80,0x31,0x80,0x30,0xC0,
0x30,0xC0,0x30,0x70,0xFC,0x1F,0x00,0x00,
0x00,0x00,0x00,0x00,0x00,0x00,
/* charDF ('Я') */
0x00,0x00,0x00,0x00,0x00,0x00,0x00,0x00,
0x00,0x00,0xF0,0xFC,0x38,0x30,0x1C,0x30,
0x0C,0x30,0x06,0x30,0x07,0x30,0x03,0x30,
0x07,0xF0,0x0C,0x30,0x18,0x30,0x18,0x30,
0x18,0x30,0x0C,0x30,0x07,0xFC,0x00,0x00,
0x00,0x00,0x00,0x00,0x00,0x00,
/* charE0 ('а') */
0x00,0x00,0x00,0x00,0x00,0x00,0x00,0x00,
0x00,0x00,0x3B,0x80,0x67,0x00,0x63,0x00,
0x63,0x00,0x33,0x00,0x1B,0x00,0x07,0x00,
0x63,0x00,0x63,0x00,0x3E,0x00,0x00,0x00,
0x00,0x00,0x00,0x00,0x00,0x00,0x00,0x00,
0x00,0x00,0x00,0x00,0x00,0x00,
/* charE1 ('б') */
0x00,0x00,0x00,0x00,0x00,0x00,0x00,0x00,
0x00,0x00,0x1E,0x00,0x31,0x80,0x30,0x80,
0x60,0xC0,0x60,0xC0,0x60,0xC0,0x60,0xC0,
0x61,0x80,0x51,0x80,0x4F,0x00,0x20,0x00,
0x30,0x00,0x1F,0x80,0x0F,0x80,0x00,0x40,
0x00,0x00,0x00,0x00,0x00,0x00,
/* charE2 ('в') */
0x00,0x00,0x00,0x00,0x00,0x00,0x00,0x00,
0x00,0x00,0x7F,0x00,0x31,0x80,0x31,0x80,
0x31,0x80,0x33,0x00,0x3E,0x00,0x33,0x00,
0x31,0x80,0x31,0x80,0x7F,0x00,0x00,0x00,
0x00,0x00,0x00,0x00,0x00,0x00,0x00,0x00,
0x00,0x00,0x00,0x00,0x00,0x00,
/* charE3 ('г') */
0x00,0x00,0x00,0x00,0x00,0x00,0x00,0x00,
0x00,0x00,0x78,0x00,0x30,0x00,0x30,0x00,
0x30,0x00,0x30,0x00,0x30,0x00,0x30,0x00,
0x30,0x80,0x31,0x80,0x7F,0x00,0x00,0x00,
0x00,0x00,0x00,0x00,0x00,0x00,0x00,0x00,
0x00,0x00,0x00,0x00,0x00,0x00,
/* charE4 ('д') */
0x00,0x00,0x00,0x00,0x80,0x40,0x80,0x40,
0xC0,0xC0,0xFF,0xC0,0x41,0x80,0x21,0x80,
0x21,0x80,0x11,0x80,0x11,0x80,0x11,0x80,
0x11,0x80,0x11,0x80,0x7F,0xC0,0x00,0x00,
0x00,0x00,0x00,0x00,0x00,0x00,0x00,0x00,
0x00,0x00,0x00,0x00,0x00,0x00,
/* charE5 ('е') */
0x00,0x00,0x00,0x00,0x00,0x00,0x00,0x00,
0x00,0x00,0x1E,0x00,0x3F,0x00,0x70,0x80,
0x60,0x00,0x60,0x00,0x60,0x00,0x7F,0x80,
0x61,0x80,0x33,0x00,0x1E,0x00,0x00,0x00,
0x00,0x00,0x00,0x00,0x00,0x00,0x00,0x00,
0x00,0x00,0x00,0x00,0x00,0x00,
/* charE6 ('ж') */
0x00,0x00,0x00,0x00,0x00,0x00,0x00,0x00,
0x00,0x00,0xE7,0x9C,0x63,0x18,0x33,0x30,
0x33,0x30,0x1B,0x60,0x0F,0xC0,0x13,0x20,
0x13,0x20,0xE3,0x1C,0xE7,0x9C,0x00,0x00,
0x00,0x00,0x00,0x00,0x00,0x00,0x00,0x00,
0x00,0x00,0x00,0x00,0x00,0x00,
/* charE7 ('з') */
0x00,0x00,0x00,0x00,0x00,0x00,0x00,0x00,
0x00,0x00,0x7C,0x00,0x8E,0x00,0x06,0x00,
0x06,0x00,0x0C,0x00,0x30,0x00,0x0C,0x00,
0x86,0x00,0xC6,0x00,0xBC,0x00,0x00,0x00,
0x00,0x00,0x00,0x00,0x00,0x00,0x00,0x00,
0x00,0x00,0x00,0x00,0x00,0x00,
/* charE8 ('и') */
0x00,0x00,0x00,0x00,0x00,0x00,0x00,0x00,
0x00,0x00,0xF1,0xE0,0x60,0xC0,0x60,0xC0,
0x70,0xC0,0x68,0xC0,0x66,0xC0,0x61,0xC0,
0x60,0xC0,0x60,0xC0,0xF1,0xE0,0x00,0x00,
0x00,0x00,0x00,0x00,0x00,0x00,0x00,0x00,
0x00,0x00,0x00,0x00,0x00,0x00,
/* charE9 ('й') */
0x00,0x00,0x00,0x00,0x00,0x00,0x00,0x00,
0x00,0x00,0xF1,0xE0,0x60,0xC0,0x60,0xC0,
0x70,0xC0,0x68,0xC0,0x66,0xC0,0x61,0xC0,
0x60,0xC0,0x60,0xC0,0xF1,0xE0,0x00,0x00,
0x1F,0x00,0x31,0x80,0x31,0x80,0x00,0x00,
0x00,0x00,0x00,0x00,0x00,0x00,
/* charEA ('к') */
0x00,0x00,0x00,0x00,0x00,0x00,0x00,0x00,
0x00,0x00,0xF1,0xC0,0x63,0x00,0x63,0x00,
0x66,0x00,0x6C,0x00,0x78,0x00,0x64,0x00,
0x62,0x00,0x62,0xC0,0xF1,0xC0,0x00,0x00,
0x00,0x00,0x00,0x00,0x00,0x00,0x00,0x00,
0x00,0x00,0x00,0x00,0x00,0x00,
/* charEB ('л') */
0x00,0x00,0x00,0x00,0x00,0x00,0x00,0x00,
0x00,0x00,0xE3,0xC0,0xD1,0x80,0x11,0x80,
0x11,0x80,0x11,0x80,0x11,0x80,0x11,0x80,
0x11,0x80,0x11,0x80,0x3F,0xC0,0x00,0x00,
0x00,0x00,0x00,0x00,0x00,0x00,0x00,0x00,
0x00,0x00,0x00,0x00,0x00,0x00,
/* charEC ('м') */
0x00,0x00,0x00,0x00,0x00,0x00,0x00,0x00,
0x00,0x00,0xE4,0x78,0x46,0x30,0x46,0x30,
0x4D,0x30,0x4D,0x30,0x58,0xB0,0x58,0xB0,
0x70,0x70,0x70,0x70,0xF0,0x38,0x00,0x00,
0x00,0x00,0x00,0x00,0x00,0x00,0x00,0x00,
0x00,0x00,0x00,0x00,0x00,0x00,
/* charED ('н') */
0x00,0x00,0x00,0x00,0x00,0x00,0x00,0x00,
0x00,0x00,0xF1,0xE0,0x60,0xC0,0x60,0xC0,
0x60,0xC0,0x60,0xC0,0x7F,0xC0,0x60,0xC0,
0x60,0xC0,0x60,0xC0,0xF1,0xE0,0x00,0x00,
0x00,0x00,0x00,0x00,0x00,0x00,0x00,0x00,
0x00,0x00,0x00,0x00,0x00,0x00,
/* charEE ('о') */
0x00,0x00,0x00,0x00,0x00,0x00,0x00,0x00,
0x00,0x00,0x1E,0x00,0x31,0x80,0x30,0x80,
0x60,0xC0,0x60,0xC0,0x60,0xC0,0x60,0xC0,
0x21,0x80,0x33,0x80,0x0E,0x00,0x00,0x00,
0x00,0x00,0x00,0x00,0x00,0x00,0x00,0x00,
0x00,0x00,0x00,0x00,0x00,0x00,
/* charEF ('п') */
0x00,0x00,0x00,0x00,0x00,0x00,0x00,0x00,
0x00,0x00,0xF1,0xE0,0x60,0xC0,0x60,0xC0,
0x60,0xC0,0x60,0xC0,0x60,0xC0,0x60,0xC0,
0x60,0xC0,0x60,0xC0,0xFF,0xE0,0x00,0x00,
0x00,0x00,0x00,0x00,0x00,0x00,0x00,0x00,
0x00,0x00,0x00,0x00,0x00,0x00,
/* charF0 ('р') */
0x00,0x00,0xF0,0x00,0x60,0x00,0x60,0x00,
0x60,0x00,0x6E,0x00,0x73,0x00,0x61,0x00,
0x61,0x80,0x61,0x80,0x61,0x80,0x61,0x80,
0x61,0x80,0xF3,0x00,0x6E,0x00,0x00,0x00,
0x00,0x00,0x00,0x00,0x00,0x00,0x00,0x00,
0x00,0x00,0x00,0x00,0x00,0x00,
/* charF1 ('с') */
0x00,0x00,0x00,0x00,0x00,0x00,0x00,0x00,
0x00,0x00,0x1C,0x00,0x3E,0x00,0x71,0x00,
0x60,0x00,0x60,0x00,0x60,0x00,0x60,0x00,
0x61,0x00,0x33,0x00,0x1E,0x00,0x00,0x00,
0x00,0x00,0x00,0x00,0x00,0x00,0x00,0x00,
0x00,0x00,0x00,0x00,0x00,0x00,
/* charF2 ('т') */
0x00,0x00,0x00,0x00,0x00,0x00,0x00,0x00,
0x00,0x00,0x1E,0x00,0x0C,0x00,0x0C,0x00,
0x0C,0x00,0x0C,0x00,0x0C,0x00,0x0C,0x00,
0x8C,0x00,0xCC,0x80,0x7F,0x80,0x00,0x00,
0x00,0x00,0x00,0x00,0x00,0x00,0x00,0x00,
0x00,0x00,0x00,0x00,0x00,0x00,
/* charF3 ('у') */
0x00,0x00,0x70,0x00,0x78,0x00,0x08,0x00,
0x04,0x00,0x04,0x00,0x06,0x00,0x0E,0x00,
0x0E,0x00,0x19,0x00,0x19,0x00,0x19,0x00,
0x30,0x80,0x70,0x80,0xF9,0x80,0x00,0x00,
0x00,0x00,0x00,0x00,0x00,0x00,0x00,0x00,
0x00,0x00,0x00,0x00,0x00,0x00,
/* charF4 ('ф') */
0x00,0x00,0x07,0x80,0x03,0x00,0x03,0x00,
0x03,0x00,0x1F,0xE0,0x33,0x30,0x63,0x18,
0x63,0x18,0x63,0x18,0x63,0x18,0x63,0x18,
0x63,0x18,0x33,0x30,0x1F,0xE0,0x03,0x00,
0x03,0x00,0x03,0x00,0x0F,0x00,0x03,0x00,
0x00,0x00,0x00,0x00,0x00,0x00,
/* charF5 ('х') */
0x00,0x00,0x00,0x00,0x00,0x00,0x00,0x00,
0x00,0x00,0xE3,0xC0,0x41,0x80,0x23,0x00,
0x16,0x00,0x0C,0x00,0x0C,0x00,0x1C,0x00,
0x32,0x00,0x61,0x00,0xF3,0xC0,0x00,0x00,
0x00,0x00,0x00,0x00,0x00,0x00,0x00,0x00,
0x00,0x00,0x00,0x00,0x00,0x00,
/* charF6 ('ц') */
0x00,0x00,0x00,0x00,0x00,0x20,0x00,0x20,
0x00,0x60,0xFF,0xC0,0x60,0xC0,0x60,0xC0,
0x60,0xC0,0x60,0xC0,0x60,0xC0,0x60,0xC0,
0x60,0xC0,0x60,0xC0,0xF1,0xE0,0x00,0x00,
0x00,0x00,0x00,0x00,0x00,0x00,0x00,0x00,
0x00,0x00,0x00,0x00,0x00,0x00,
/* charF7 ('ч') */
0x00,0x00,0x00,0x00,0x00,0x00,0x00,0x00,
0x00,0x00,0x03,0xC0,0x01,0x80,0x01,0x80,
0x01,0x80,0x3F,0x80,0x31,0x80,0x31,0x80,
0x31,0x80,0x31,0x80,0x7B,0xC0,0x00,0x00,
0x00,0x00,0x00,0x00,0x00,0x00,0x00,0x00,
0x00,0x00,0x00,0x00,0x00,0x00,
/* charF8 ('ш') */
0x00,0x00,0x00,0x00,0x00,0x00,0x00,0x00,
0x00,0x00,0x7F,0xFE,0x31,0x8C,0x31,0x8C,
0x31,0x8C,0x31,0x8C,0x31,0x8C,0x31,0x8C,
0x31,0x8C,0x31,0x8C,0x7B,0xDE,0x00,0x00,
0x00,0x00,0x00,0x00,0x00,0x00,0x00,0x00,
0x00,0x00,0x00,0x00,0x00,0x00,
/* charF9 ('щ') */
0x00,0x00,0x00,0x00,0x00,0x02,0x00,0x02,
0x00,0x06,0x7F,0xFC,0x31,0x8C,0x31,0x8C,
0x31,0x8C,0x31,0x8C,0x31,0x8C,0x31,0x8C,
0x31,0x8C,0x31,0x8C,0x7B,0xDE,0x00,0x00,
0x00,0x00,0x00,0x00,0x00,0x00,0x00,0x00,
0x00,0x00,0x00,0x00,0x00,0x00,
/* charFA ('ъ') */
0x00,0x00,0x00,0x00,0x00,0x00,0x00,0x00,
0x00,0x00,0x3F,0x80,0x18,0xC0,0x18,0xC0,
0x18,0xC0,0x18,0xC0,0x1F,0x80,0x18,0x00,
0x98,0x00,0xD8,0x00,0x7C,0x00,0x00,0x00,
0x00,0x00,0x00,0x00,0x00,0x00,0x00,0x00,
0x00,0x00,0x00,0x00,0x00,0x00,
/* charFB ('ы') */
0x00,0x00,0x00,0x00,0x00,0x00,0x00,0x00,
0x00,0x00,0xFE,0x78,0x63,0x30,0x63,0x30,
0x63,0x30,0x63,0x30,0x7E,0x30,0x60,0x30,
0x60,0x30,0x60,0x30,0xF0,0x78,0x00,0x00,
0x00,0x00,0x00,0x00,0x00,0x00,0x00,0x00,
0x00,0x00,0x00,0x00,0x00,0x00,
/* charFC ('ь') */
0x00,0x00,0x00,0x00,0x00,0x00,0x00,0x00,
0x00,0x00,0x7F,0x00,0x31,0x80,0x31,0x80,
0x31,0x80,0x31,0x80,0x3F,0x00,0x30,0x00,
0x30,0x00,0x30,0x00,0x78,0x00,0x00,0x00,
0x00,0x00,0x00,0x00,0x00,0x00,0x00,0x00,
0x00,0x00,0x00,0x00,0x00,0x00,
/* charFD ('э') */
0x00,0x00,0x00,0x00,0x00,0x00,0x00,0x00,
0x00,0x00,0x7C,0x00,0xC6,0x00,0x02,0x00,
0x03,0x00,0x03,0x00,0x1F,0x00,0x03,0x00,
0x43,0x00,0x66,0x00,0x5C,0x00,0x00,0x00,
0x00,0x00,0x00,0x00,0x00,0x00,0x00,0x00,
0x00,0x00,0x00,0x00,0x00,0x00,
/* charFE ('ю') */
0x00,0x00,0x00,0x00,0x00,0x00,0x00,0x00,
0x00,0x00,0x78,0xF0,0x31,0x8C,0x31,0x84,
0x33,0x06,0x33,0x06,0x3F,0x06,0x33,0x06,
0x33,0x0C,0x31,0x8C,0x78,0xF8,0x00,0x00,
0x00,0x00,0x00,0x00,0x00,0x00,0x00,0x00,
0x00,0x00,0x00,0x00,0x00,0x00,
/* charFF ('я') */
0x00,0x00,0x00,0x00,0x00,0x00,0x00,0x00,
0x00,0x00,0xE7,0x80,0x63,0x00,0x33,0x00,
0x33,0x00,0x1B,0x00,0x1F,0x00,0x33,0x00,
0x63,0x00,0x63,0x00,0x3F,0x80,0x00,0x00,
0x00,0x00,0x00,0x00,0x00,0x00,0x00,0x00,
0x00,0x00,0x00,0x00,0x00,0x00
};

/* USER CODE END 0 */

int main(void)
{

  /* MCU Configuration----------------------------------------------------------*/

  /* Reset of all peripherals, Initializes the Flash interface and the Systick. */
  HAL_Init();

  /* Configure the system clock */
  SystemClock_Config();

  /* Initialize all configured peripherals */
  MX_GPIO_Init();
  MX_USART1_UART_Init();

  /* USER CODE BEGIN 2 */
	TimesNewRoman16[3] = 'f';
  /* USER CODE END 2 */

  /* Infinite loop */
  /* USER CODE BEGIN WHILE */
	uint32_t i = 0;
  while (1)
  {
		printf("d %d\n", i++);
		HAL_Delay(100);
  /* USER CODE END WHILE */

  }

}

/** System Clock Configuration
*/
void SystemClock_Config(void)
{

  RCC_OscInitTypeDef RCC_OscInitStruct;
  RCC_ClkInitTypeDef RCC_ClkInitStruct;

  RCC_OscInitStruct.OscillatorType = RCC_OSCILLATORTYPE_HSE;
  RCC_OscInitStruct.HSEState = RCC_HSE_ON;
  RCC_OscInitStruct.HSEPredivValue = RCC_HSE_PREDIV_DIV1;
  RCC_OscInitStruct.PLL.PLLState = RCC_PLL_ON;
  RCC_OscInitStruct.PLL.PLLSource = RCC_PLLSOURCE_HSE;
  RCC_OscInitStruct.PLL.PLLMUL = RCC_PLL_MUL9;
  HAL_RCC_OscConfig(&RCC_OscInitStruct);

  RCC_ClkInitStruct.ClockType = RCC_CLOCKTYPE_HCLK|RCC_CLOCKTYPE_SYSCLK
                              |RCC_CLOCKTYPE_PCLK1|RCC_CLOCKTYPE_PCLK2;
  RCC_ClkInitStruct.SYSCLKSource = RCC_SYSCLKSOURCE_PLLCLK;
  RCC_ClkInitStruct.AHBCLKDivider = RCC_SYSCLK_DIV1;
  RCC_ClkInitStruct.APB1CLKDivider = RCC_HCLK_DIV2;
  RCC_ClkInitStruct.APB2CLKDivider = RCC_HCLK_DIV1;
  HAL_RCC_ClockConfig(&RCC_ClkInitStruct, FLASH_LATENCY_2);

  HAL_SYSTICK_Config(HAL_RCC_GetHCLKFreq()/1000);

  HAL_SYSTICK_CLKSourceConfig(SYSTICK_CLKSOURCE_HCLK);

  /* SysTick_IRQn interrupt configuration */
  HAL_NVIC_SetPriority(SysTick_IRQn, 0, 0);
}

/************************ (C) COPYRIGHT STMicroelectronics *****END OF FILE****/
